VERSION ""

NS_ :

BS_:

BU_: SME EDME REME KLE GWS RDME

BO_ 3221225472 VECTOR__INDEPENDENT_SIG_MSG: 0 Vector__XXX
 SG_ FC_Contactor_Test : 0|1@0+ (1,0) [0|1] "" Vector__XXX
 SG_ Displayed_SOC : 0|8@1+ (0.5,0) [0|100] "%" Vector__XXX
 SG_ CV_Setpoint : 0|12@1+ (0.1,0) [0|409.4] "Volts" Vector__XXX
 SG_ New_Signal_79 : 16|8@1+ (1,0) [0|0] "" Vector__XXX
 SG_ Frame0_1D6 : 0|8@1+ (1,0) [0|0] "" Vector__XXX
 SG_ Frame1_1D6 : 8|8@1+ (1,0) [0|0] "" Vector__XXX
 SG_ DataHighVol : 0|8@1+ (1,0) [0|0] "" Vector__XXX
 SG_ I_Available : 24|16@1+ (0.1,0) [-500|500] "Amps" Vector__XXX
 SG_ V_Avail : 8|16@1+ (0.1,0) [0|1000] "Volts" Vector__XXX
 SG_ Thresh_V : 40|16@1+ (0.1,0) [0|600] "V" Vector__XXX
 SG_ Weld_Det_En : 0|2@1+ (1,0) [0|4] "" Vector__XXX
 SG_ internal_charger_status : 2|4@1+ (1,0) [0|16] "" Vector__XXX
 SG_ CCS_Protocol : 56|8@1+ (1,0) [0|255] "" Vector__XXX
 SG_ Iso_Status : 6|2@1+ (1,0) [0|3] "" Vector__XXX
 SG_ MinV_Avail : 0|16@1+ (0.1,0) [0|1000] "Volts" Vector__XXX
 SG_ Min_I_Avail : 16|12@1+ (0.1,0) [0|410] "A" Vector__XXX
 SG_ Energy_Transmitted : 56|8@1+ (0.25,0) [0|63] "kWh" Vector__XXX
 SG_ Power_Limit : 52|2@1+ (1,0) [0|2] "" Vector__XXX
 SG_ Battery_Compatability : 38|2@1+ (1,0) [0|4] "" Vector__XXX
 SG_ CHG_Volts : 0|16@1+ (0.1,0) [0|1] "Volts" Vector__XXX
 SG_ CHG_Amps : 16|16@1+ (0.1,0) [-500|500] "Amps" Vector__XXX
 SG_ I_Limit : 44|2@1+ (1,0) [0|1] "" Vector__XXX
 SG_ V_Limit : 46|2@1+ (1,0) [0|3] "" Vector__XXX
 SG_ Batt_Malf : 40|2@1+ (1,0) [0|3] "" Vector__XXX
 SG_ Charge_Status : 32|2@1+ (1,0) [0|3] "" Vector__XXX
 SG_ CCS_Malf : 34|2@1+ (1,0) [0|3] "" Vector__XXX
 SG_ DC_Chg_Stop : 42|2@1+ (1,0) [0|3] "" Vector__XXX
 SG_ Pilot_Current : 0|8@1+ (1,0) [0|63] "Amps" Vector__XXX
 SG_ Cable_Current : 8|8@1+ (1,0) [0|63] "Amps" Vector__XXX
 SG_ FC_Voltage : 56|8@1+ (2,0) [0|500] "Volts" Vector__XXX
 SG_ Pilot_Status : 32|3@1+ (1,0) [0|1] "" Vector__XXX
 SG_ PP_Status : 23|2@1+ (1,0) [0|1] "" Vector__XXX
 SG_ CP_Lock_Status : 26|2@1+ (1,0) [0|1] "" Vector__XXX
 SG_ CHG_Flap_Status : 24|2@1+ (1,0) [0|4] "" Vector__XXX
 SG_ Plug_Connection : 37|2@1+ (1,0) [0|4] "" Vector__XXX
 SG_ Charge_End_Sig : 20|2@1+ (1,0) [0|4] "" Vector__XXX
 SG_ HW_Charger_EN : 22|2@1+ (1,0) [0|1] "" Vector__XXX
 SG_ CCS_Plug : 35|2@1+ (1,0) [0|1] "" Vector__XXX
 SG_ Charging_Type : 48|8@1+ (1,0) [0|1] "" Vector__XXX
 SG_ DC_Chg_Volts : 39|9@1+ (2,0) [0|1000] "V" Vector__XXX
 SG_ FC_Contactor_Info : 20|4@1+ (1,0) [0|15] "" Vector__XXX
 SG_ FC_Contactor_State : 18|2@1+ (1,0) [0|3] "" Vector__XXX
 SG_ ChargeFlap_Status : 16|2@1+ (1,0) [0|4] "" Vector__XXX
 SG_ Hook_Pos : 0|2@1+ (1,0) [0|3] "" Vector__XXX
 SG_ Hook_Lock : 2|2@1+ (1,0) [0|3] "" Vector__XXX
 SG_ Chg_End : 18|2@1+ (1,0) [0|1] "" Vector__XXX
 SG_ FC_End : 16|2@1+ (1,0) [0|1] "" Vector__XXX
 SG_ Target_CHG_Ph : 20|4@1+ (1,0) [0|1] "" Vector__XXX
 SG_ Time2Go : 0|16@1+ (1,0) [0|65534] "Mins" Vector__XXX
 SG_ Target_Volts : 24|14@1+ (0.1,0) [0|1000] "V" Vector__XXX
 SG_ frame0_1d6 : 0|8@1+ (1,0) [0|0] "" Vector__XXX
 SG_ frame1_1d6 : 8|8@1+ (1,0) [0|0] "" Vector__XXX
 SG_ Frame_0_1EE : 0|8@1+ (1,0) [0|0] "" Vector__XXX
 SG_ Frame_1_1EE : 8|8@1+ (1,0) [0|0] "" Vector__XXX
 SG_ POSITION_1 : 16|16@1+ (0.005,0) [0|1] "" Vector__XXX
 SG_ lock_button : 22|2@1+ (1,0) [0|4] "" Vector__XXX
 SG_ doors : 8|8@1+ (1,0) [0|0] "" Vector__XXX
 SG_ locks : 0|8@1+ (1,0) [0|0] "" Vector__XXX
 SG_ boot : 16|6@1+ (1,0) [0|0] "" Vector__XXX
 SG_ UnusedFF : 24|40@1+ (1,0) [0|0] "" Vector__XXX
 SG_ Time_to_FC_SOC : 40|16@1+ (10,0) [0|655320] "Secs" Vector__XXX
 SG_ Time_to_SOC : 24|16@1+ (10,0) [0|655320] "Secs" Vector__XXX
 SG_ FC_SOC : 56|8@1+ (0.5,0) [0|100] "%" Vector__XXX
 SG_ CHG_I_Lim : 16|8@1+ (1,0) [0|254] "Amps" Vector__XXX
 SG_ CHG_V_Lim : 0|14@1- (0.1,0) [0|1000] "Volts" Vector__XXX
 SG_ BatteryVoltage : 16|12@1+ (1,0) [0|0] "" Vector__XXX
 SG_ Total_Battery : 40|12@1+ (0.02,0) [0|82] "kWh" Vector__XXX
 SG_ TemperatureMaxMaybe : 16|8@1+ (1,0) [0|0] "" Vector__XXX
 SG_ NewSignal_0033 : 24|4@1+ (1,0) [0|0] "" Vector__XXX
 SG_ NewSignal_0035 : 8|8@1+ (1,0) [0|0] "" Vector__XXX
 SG_ NewSignal_0039 : 8|2@1+ (1,0) [0|0] "" Vector__XXX

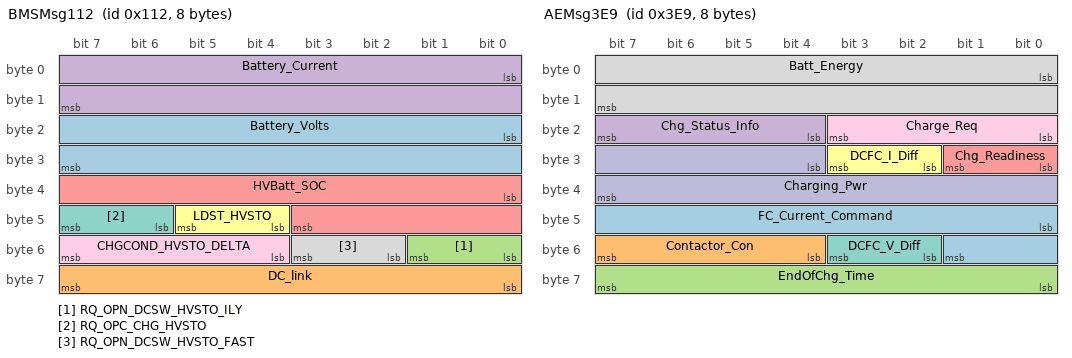
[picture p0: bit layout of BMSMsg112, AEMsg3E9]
BO_ 274 BMSMsg112: 8 SME
 SG_ Battery_Volts : 16|16@1+ (0.1,0) [0|819] "Volts" Vector__XXX
 SG_ DC_link : 56|8@1+ (4,0) [0|820] "Volts" Vector__XXX
 SG_ RQ_OPN_DCSW_HVSTO_ILY : 48|2@1+ (1,0) [0|16] "" Vector__XXX
 SG_ Battery_Current : 0|16@1+ (0.1,-819.2) [0|819.2] "Amps" Vector__XXX
 SG_ HVBatt_SOC : 32|12@1+ (0.1,0) [0|100] "%" Vector__XXX
 SG_ LDST_HVSTO : 44|2@1+ (1,0) [0|0] "" Vector__XXX
 SG_ RQ_OPC_CHG_HVSTO : 46|2@1+ (1,0) [0|0] "" Vector__XXX
 SG_ RQ_OPN_DCSW_HVSTO_FAST : 50|2@1+ (1,0) [0|3] "status" Vector__XXX
 SG_ CHGCOND_HVSTO_DELTA : 52|4@1+ (0.00834,0) [0|0.1] "%" Vector__XXX

BO_ 1001 AEMsg3E9: 8 EDME
 SG_ FC_Current_Command : 40|10@1- (1,0) [-500|500] "Amps" Vector__XXX
 SG_ Contactor_Con : 52|4@1+ (1,0) [0|16] "" Vector__XXX
 SG_ EndOfChg_Time : 56|8@1+ (1,0) [0|255] "Mins" Vector__XXX
 SG_ Chg_Status_Info : 20|4@1+ (1,0) [0|3] "" Vector__XXX
 SG_ Chg_Readiness : 24|2@1+ (1,0) [0|3] "" Vector__XXX
 SG_ DCFC_I_Diff : 26|2@1+ (1,0) [0|3] "" Vector__XXX
 SG_ DCFC_V_Diff : 50|2@1+ (1,0) [0|3] "" Vector__XXX
 SG_ Batt_Energy : 0|16@1+ (1,0) [0|65534] "Wh" Vector__XXX
 SG_ Charge_Req : 16|4@1+ (1,0) [0|16] "" Vector__XXX
 SG_ Charging_Pwr : 28|12@1+ (25,0) [0|102350] "Watts" Vector__XXX

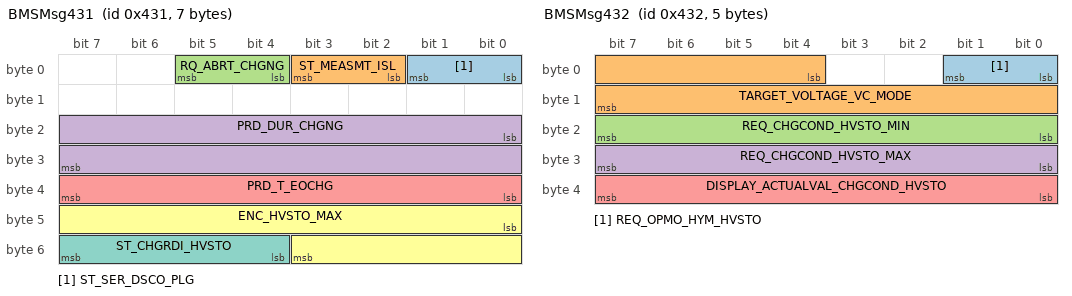
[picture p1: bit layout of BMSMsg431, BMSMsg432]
BO_ 1073 BMSMsg431: 7 SME
 SG_ ST_SER_DSCO_PLG : 0|2@1+ (1,0) [0|3] "status" Vector__XXX
 SG_ ST_MEASMT_ISL : 2|2@1+ (1,0) [0|3] "status" Vector__XXX
 SG_ RQ_ABRT_CHGNG : 4|2@1+ (1,0) [0|0] "" Vector__XXX
 SG_ PRD_DUR_CHGNG : 16|16@1+ (1,0) [0|65532] "minutes" Vector__XXX
 SG_ PRD_T_EOCHG : 32|8@1+ (1,0) [0|1270] "minutes" Vector__XXX
 SG_ ENC_HVSTO_MAX : 40|12@1+ (0.02,0) [0|81.88] "kWh" Vector__XXX
 SG_ ST_CHGRDI_HVSTO : 52|4@1+ (1,0) [0|0] "" Vector__XXX

BO_ 1074 BMSMsg432: 5 SME
 SG_ REQ_OPMO_HYM_HVSTO : 0|2@1+ (1,0) [0|3] "status" Vector__XXX
 SG_ TARGET_VOLTAGE_VC_MODE : 4|12@1+ (0.1,0) [0|409.4] "V" Vector__XXX
 SG_ REQ_CHGCOND_HVSTO_MIN : 16|8@1+ (0.5,0) [0|100] "%" Vector__XXX
 SG_ REQ_CHGCOND_HVSTO_MAX : 24|8@1+ (0.5,0) [0|100] "%" Vector__XXX
 SG_ DISPLAY_ACTUALVAL_CHGCOND_HVSTO : 32|8@1+ (0.5,0) [0|100] "%" Vector__XXX

BO_ 808 EDMEMsg328: 6 EDME
 SG_ Seconds_ctr : 0|32@1+ (1,0) [0|2704] "S" Vector__XXX
 SG_ Day_ctr : 32|16@1+ (1,0) [0|65534] "Days" Vector__XXX

BO_ 303 EDMEMsg12f: 8 EDME
 SG_ CRC_12F : 0|8@1+ (1,0) [0|255] "CRC" Vector__XXX
 SG_ ALIVE_COUNTER_KL : 8|4@1+ (1,0) [0|14] "counter" Vector__XXX
 SG_ ST_VEH_CON : 12|4@1+ (1,0) [0|15] "status" Vector__XXX
 SG_ ST_KL : 16|4@1+ (1,0) [0|15] "status" Vector__XXX
 SG_ ST_KL_DIV : 20|4@1+ (1,0) [0|15] "status" Vector__XXX
 SG_ ST_KL_30B : 24|4@1+ (1,0) [0|15] "status" Vector__XXX
 SG_ ST_KL_15N : 28|4@1+ (1,0) [0|15] "status" Vector__XXX
 SG_ ST_KL_KEY_VLD : 32|4@1+ (1,0) [0|15] "status" Vector__XXX
 SG_ ST_PLK : 36|2@1+ (1,0) [0|3] "status" Vector__XXX
 SG_ CON_CLT_SW : 38|2@1+ (1,0) [0|3] "" Vector__XXX
 SG_ CTR_ENG_STOP : 40|2@1+ (1,0) [0|3] "counter" Vector__XXX
 SG_ ST_STCD_PENG : 42|2@1+ (1,0) [0|3] "status" Vector__XXX
 SG_ ST_OP_MSA : 44|2@1+ (1,0) [0|3] "status" Vector__XXX
 SG_ ST_SSP : 46|2@1+ (1,0) [0|3] "status" Vector__XXX
 SG_ RWDT_BLS : 48|4@1+ (1,0) [0|15] "" Vector__XXX
 SG_ ST_KL_50_MSA : 52|2@1+ (1,0) [0|3] "status" Vector__XXX
 SG_ RQ_DRVG_RDI : 54|2@1+ (1,0) [0|3] "" Vector__XXX
 SG_ ST_KL_DBG : 56|8@1+ (1,0) [0|255] "status" Vector__XXX

BO_ 1000 AEMsg3e8: 2 EDME
 SG_ RQ_MIL_DIAG_OBD_ENGMG_EL : 0|2@1+ (1,0) [0|4] "" Vector__XXX
 SG_ RQ_RST_OBD_DIAG : 2|2@1+ (1,0) [0|0] "" Vector__XXX

BO_ 816 OdometerMsg330: 8 EDME
 SG_ Odometer : 0|24@1+ (1,0) [0|16777200] "km" Vector__XXX

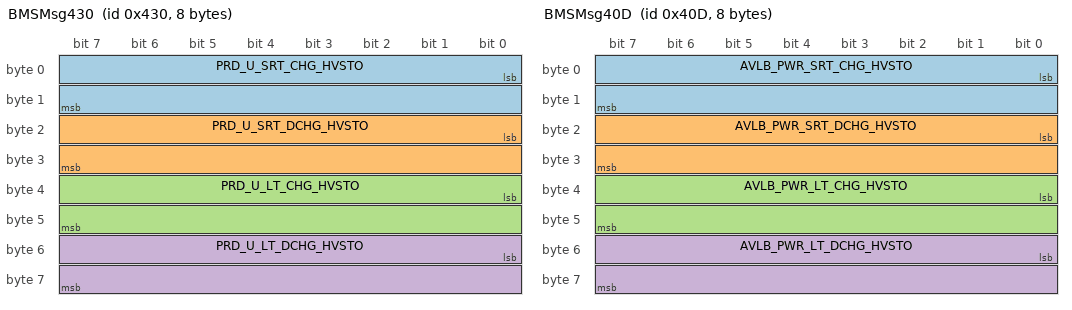
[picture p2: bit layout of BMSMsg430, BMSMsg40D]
BO_ 1072 BMSMsg430: 8 SME
 SG_ PRD_U_SRT_CHG_HVSTO : 0|16@1+ (1,0.1) [0|819] "V" Vector__XXX
 SG_ PRD_U_SRT_DCHG_HVSTO : 16|16@1+ (1,0.1) [0|819] "V" Vector__XXX
 SG_ PRD_U_LT_CHG_HVSTO : 32|16@1+ (1,0.1) [0|819] "V" Vector__XXX
 SG_ PRD_U_LT_DCHG_HVSTO : 48|16@1+ (1,0.1) [0|819] "V" Vector__XXX

BO_ 506 BMSMsg1FA: 8 SME
 SG_ ST_ERR_ISL_EXTN_BN_HV : 0|2@1+ (1,0) [0|3] "status" Vector__XXX
 SG_ ST_ERR_ISL_INTL_BN_HV : 2|2@1+ (1,0) [0|3] "status" Vector__XXX
 SG_ RQ_COOL_HVSTO : 4|2@1+ (1,0) [0|3] "status" Vector__XXX
 SG_ ST_VA_COOL_HVSTO : 6|2@1+ (1,0) [0|3] "status" Vector__XXX
 SG_ ST_ERR_LOKG_HVSTO : 8|2@1+ (1,0) [0|3] "status" Vector__XXX
 SG_ ST_PRCHRG_LOKD_HVSTO : 10|2@1+ (1,0) [0|3] "status" Vector__XXX
 SG_ ST_DCSW_HVSTO : 12|2@1+ (1,0) [0|3] "status" Vector__XXX
 SG_ ST_EMMOD_HVSTO : 14|2@1+ (1,0) [0|3] "status" Vector__XXX
 SG_ RQ_SER_HVSTO : 16|2@1+ (1,0) [0|3] "status" Vector__XXX
 SG_ ERR_EMMOD_HVSTO : 18|2@1+ (1,0) [0|3] "status" Vector__XXX
 SG_ ST_ERR_DCSW_HVSTO : 20|2@1+ (1,0) [0|3] "status" Vector__XXX
 SG_ ST_WARN_ISL_BN_HV : 22|2@1+ (1,0) [0|3] "status" Vector__XXX
 SG_ ST_CSOV_HVSTO : 24|4@1+ (1,0) [0|15] "status" Vector__XXX
 SG_ AVL_TEMP_HVSTO : 32|8@1+ (1,-50) [-50|204] "C" Vector__XXX
 SG_ AVL_TEMP_HTEX_HVSTO : 40|8@1+ (1,-50) [-50|204] "C" Vector__XXX
 SG_ AVL_TEMP_HVSTO_MIN : 48|8@1+ (1,-50) [-50|202] "C" Vector__XXX
 SG_ AVL_TEMP_HVSTO_MAX : 56|8@1+ (1,-50) [-50|202] "C" Vector__XXX

BO_ 1037 BMSMsg40D: 8 SME
 SG_ AVLB_PWR_SRT_CHG_HVSTO : 0|16@1+ (3,0) [0|196596] "W" Vector__XXX
 SG_ AVLB_PWR_SRT_DCHG_HVSTO : 16|16@1+ (3,0) [0|196596] "W" Vector__XXX
 SG_ AVLB_PWR_LT_CHG_HVSTO : 32|16@1+ (3,0) [0|196596] "W" Vector__XXX
 SG_ AVLB_PWR_LT_DCHG_HVSTO : 48|16@1+ (3,0) [0|196596] "W" Vector__XXX

BO_ 767 BMSMsg2FF: 6 SME
 SG_ AVL_PWR_HT_HVSTO : 4|12@1+ (1,0) [0|4094] "W" Vector__XXX

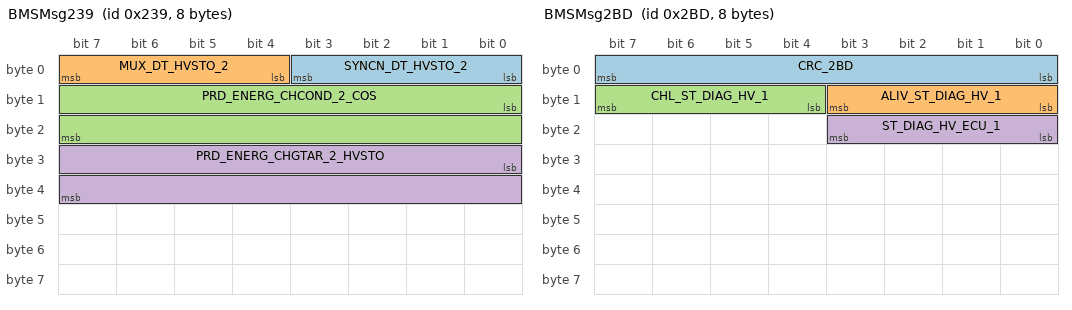
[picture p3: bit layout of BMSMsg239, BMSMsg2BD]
BO_ 569 BMSMsg239: 8 SME
 SG_ SYNCN_DT_HVSTO_2 : 0|4@1+ (1,0) [0|14] "" Vector__XXX
 SG_ MUX_DT_HVSTO_2 : 4|4@1+ (1,0) [0|0] "" Vector__XXX
 SG_ PRD_ENERG_CHCOND_2_COS : 8|16@1+ (1,0) [0|65534] "Wh" Vector__XXX
 SG_ PRD_ENERG_CHGTAR_2_HVSTO : 24|16@1+ (0.02,0) [0|1310.64] "kWh" Vector__XXX

BO_ 701 BMSMsg2BD: 8 SME
 SG_ CRC_2BD : 0|8@1+ (1,0) [0|0] "" Vector__XXX
 SG_ ALIV_ST_DIAG_HV_1 : 8|4@1+ (1,0) [0|15] "counter" Vector__XXX
 SG_ CHL_ST_DIAG_HV_1 : 12|4@1+ (1,0) [0|15] "counter" Vector__XXX
 SG_ ST_DIAG_HV_ECU_1 : 16|4@1+ (1,0) [0|15] "status" Vector__XXX

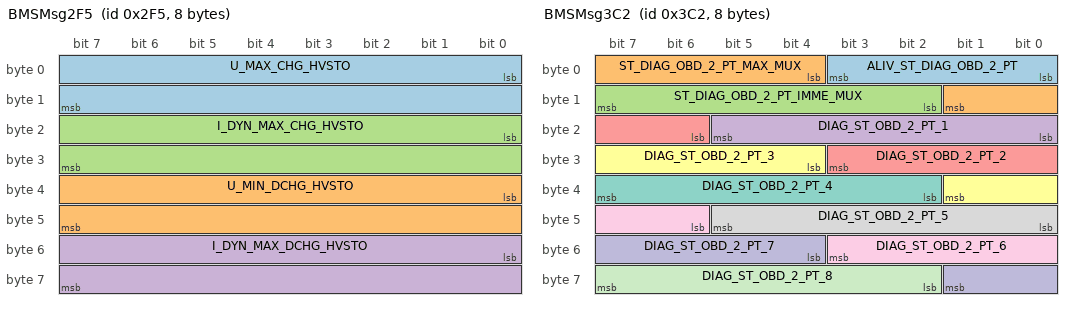
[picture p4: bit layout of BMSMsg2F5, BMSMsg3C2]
BO_ 757 BMSMsg2F5: 8 SME
 SG_ U_MAX_CHG_HVSTO : 0|16@1+ (0.1,0) [0|819] "V" Vector__XXX
 SG_ U_MIN_DCHG_HVSTO : 32|16@1+ (0.1,0) [0|819] "V" Vector__XXX
 SG_ I_DYN_MAX_CHG_HVSTO : 16|16@1+ (0.1,-819.2) [-819.2|819] "A" Vector__XXX
 SG_ I_DYN_MAX_DCHG_HVSTO : 48|16@1+ (0.1,-819.2) [-819.2|819] "A" Vector__XXX

BO_ 962 BMSMsg3C2: 8 SME
 SG_ ALIV_ST_DIAG_OBD_2_PT : 0|4@1+ (1,0) [0|15] "counter" Vector__XXX
 SG_ ST_DIAG_OBD_2_PT_MAX_MUX : 4|6@1+ (1,0) [4|60] "mux" Vector__XXX
 SG_ ST_DIAG_OBD_2_PT_IMME_MUX : 10|6@1+ (1,0) [4|60] "mux" Vector__XXX
 SG_ DIAG_ST_OBD_2_PT_1 : 16|6@1+ (1,0) [0|0] "" Vector__XXX
 SG_ DIAG_ST_OBD_2_PT_2 : 22|6@1+ (1,0) [0|0] "" Vector__XXX
 SG_ DIAG_ST_OBD_2_PT_3 : 28|6@1+ (1,0) [0|0] "" Vector__XXX
 SG_ DIAG_ST_OBD_2_PT_4 : 34|6@1+ (1,0) [0|0] "" Vector__XXX
 SG_ DIAG_ST_OBD_2_PT_5 : 40|6@1+ (1,0) [0|0] "" Vector__XXX
 SG_ DIAG_ST_OBD_2_PT_6 : 46|6@1+ (1,0) [0|0] "" Vector__XXX
 SG_ DIAG_ST_OBD_2_PT_7 : 52|6@1+ (1,0) [0|0] "" Vector__XXX
 SG_ DIAG_ST_OBD_2_PT_8 : 58|6@1+ (1,0) [0|0] "" Vector__XXX

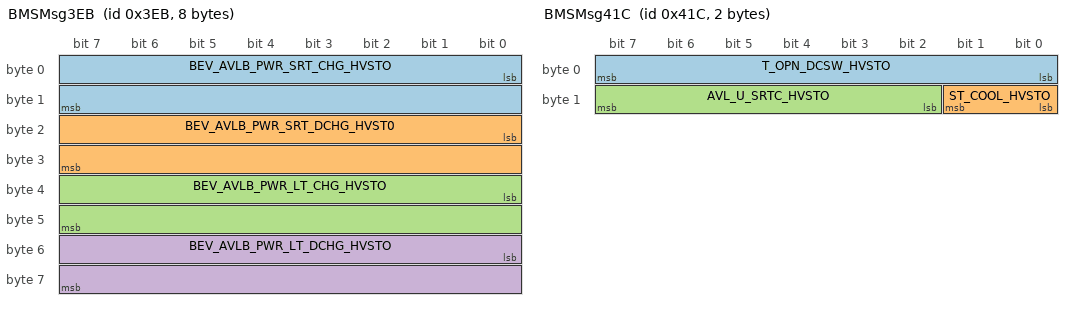
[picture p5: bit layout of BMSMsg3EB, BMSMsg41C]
BO_ 1003 BMSMsg3EB: 8 SME
 SG_ BEV_AVLB_PWR_SRT_CHG_HVSTO : 0|16@1+ (3,0) [0|196602] "W" Vector__XXX
 SG_ BEV_AVLB_PWR_SRT_DCHG_HVST0 : 16|16@1+ (3,0) [0|196602] "W" Vector__XXX
 SG_ BEV_AVLB_PWR_LT_CHG_HVSTO : 32|16@1+ (3,0) [0|196602] "W" Vector__XXX
 SG_ BEV_AVLB_PWR_LT_DCHG_HVSTO : 48|16@1+ (3,0) [0|196602] "W" Vector__XXX

BO_ 867 BMSMsg363: 8 SME
 SG_ IDENT_HVSTO : 0|32@1+ (1,0) [0|4294967295] "serial" Vector__XXX

BO_ 1287 BMSMsg507: 8 SME
 SG_ NM2_AUTOSAR_RES_ACAN : 0|32@1+ (1,0) [0|0] "" Vector__XXX
 SG_ NM2_USR_DT_ACAN : 32|32@1+ (1,0) [0|0] "" Vector__XXX

BO_ 1415 BMSMsg587: 8 SME
 SG_ ID2 : 0|8@1+ (1,0) [0|0] "" Vector__XXX
 SG_ DT_Dynamic : 8|56@1+ (1,0) [0|0] "" Vector__XXX

BO_ 1052 BMSMsg41C: 2 SME
 SG_ T_OPN_DCSW_HVSTO : 0|8@1+ (1,0) [0|0] "" Vector__XXX
 SG_ ST_COOL_HVSTO : 8|2@1+ (1,0) [0|3] "status" Vector__XXX
 SG_ AVL_U_SRTC_HVSTO : 10|6@1+ (1,0) [0|0] "" Vector__XXX

BO_ 1543 BMSMsg607: 8 SME

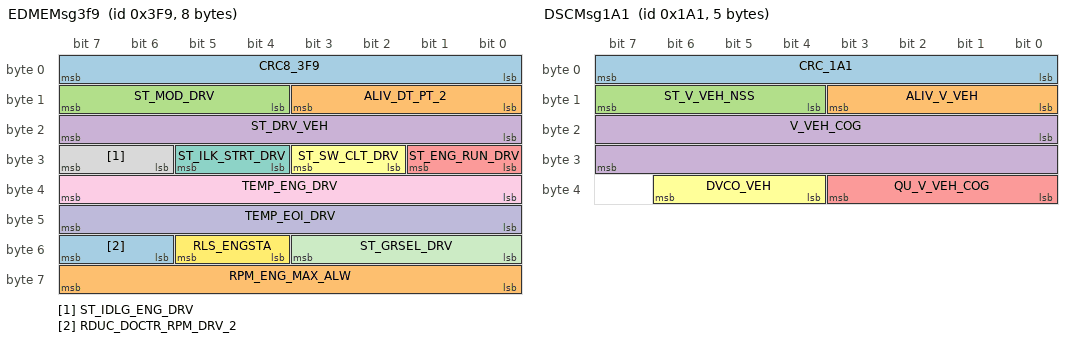
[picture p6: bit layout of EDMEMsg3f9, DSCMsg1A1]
BO_ 1017 EDMEMsg3f9: 8 EDME
 SG_ CRC8_3F9 : 0|8@1+ (1,0) [0|255] "CRC" Vector__XXX
 SG_ ALIV_DT_PT_2 : 8|4@1+ (1,0) [0|16] "counter" Vector__XXX
 SG_ ST_MOD_DRV : 12|4@1+ (1,0) [0|16] "status" Vector__XXX
 SG_ ST_DRV_VEH : 16|8@1+ (1,0) [0|0] "status" Vector__XXX
 SG_ ST_ENG_RUN_DRV : 24|2@1+ (1,0) [0|0] "status" Vector__XXX
 SG_ ST_SW_CLT_DRV : 26|2@1+ (1,0) [0|0] "status" Vector__XXX
 SG_ ST_ILK_STRT_DRV : 28|2@1+ (1,0) [0|0] "status" Vector__XXX
 SG_ ST_IDLG_ENG_DRV : 30|2@1+ (1,0) [0|0] "" Vector__XXX
 SG_ TEMP_ENG_DRV : 32|8@1+ (1,-48) [-48|144] "" Vector__XXX
 SG_ TEMP_EOI_DRV : 40|8@1+ (1,-48) [-48|170] "" Vector__XXX
 SG_ ST_GRSEL_DRV : 48|4@1+ (1,0) [0|0] "" Vector__XXX
 SG_ RLS_ENGSTA : 52|2@1+ (1,0) [0|0] "" Vector__XXX
 SG_ RDUC_DOCTR_RPM_DRV_2 : 54|2@1+ (1,0) [0|0] "" Vector__XXX
 SG_ RPM_ENG_MAX_ALW : 56|8@1+ (1,0) [0|0] "" Vector__XXX

BO_ 417 DSCMsg1A1: 5 Vector__XXX
 SG_ CRC_1A1 : 0|8@1+ (1,0) [0|255] "CRCV" Vector__XXX
 SG_ ALIV_V_VEH : 8|4@1+ (1,0) [0|15] "counter" Vector__XXX
 SG_ ST_V_VEH_NSS : 12|4@1+ (1,0) [0|0] "" Vector__XXX
 SG_ V_VEH_COG : 16|16@1+ (0.015625,0) [0|350] "km/h" Vector__XXX
 SG_ QU_V_VEH_COG : 32|4@1+ (1,0) [0|0] "status" Vector__XXX
 SG_ DVCO_VEH : 36|3@1+ (1,0) [0|0] "" Vector__XXX

BO_ 896 VINMsg380: 7 EDME
 SG_ VIN : 0|56@1+ (1,0) [0|0] "" Vector__XXX

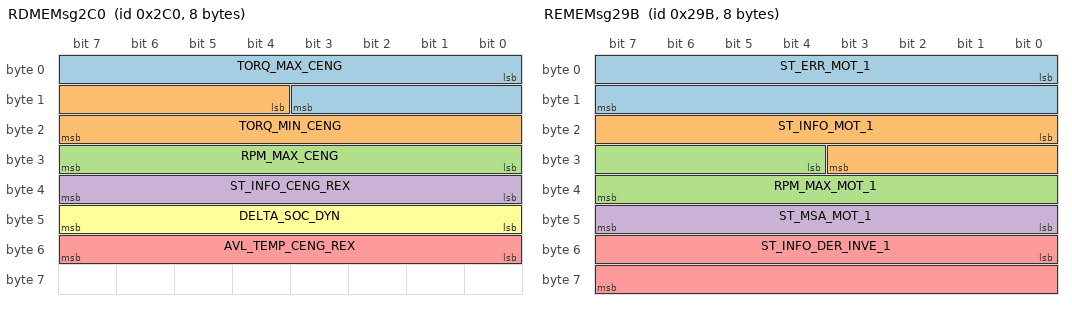
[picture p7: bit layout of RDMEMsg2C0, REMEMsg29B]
BO_ 704 RDMEMsg2C0: 8 REME
 SG_ TORQ_MAX_CENG : 0|12@1+ (0.5,-1023.5) [-1023.5|1022.5] "Nm" Vector__XXX
 SG_ TORQ_MIN_CENG : 12|12@1+ (0.5,-1023.5) [-1023.5|1022.5] "Nm" Vector__XXX
 SG_ RPM_MAX_CENG : 24|8@1+ (40,0) [0|10000] "rpm" Vector__XXX
 SG_ ST_INFO_CENG_REX : 32|8@1+ (1,0) [0|255] "status" Vector__XXX
 SG_ AVL_TEMP_CENG_REX : 48|8@1+ (1,-48) [-48|204] "C" Vector__XXX
 SG_ DELTA_SOC_DYN : 40|8@1+ (1,0) [0|0] "" Vector__XXX

BO_ 165 UnknownMsg0A5: 8 Vector__XXX

BO_ 168 UnknownMsg0A8: 8 Vector__XXX

BO_ 205 UnknownMsg0CD: 8 Vector__XXX

BO_ 667 REMEMsg29B: 8 REME
 SG_ ST_ERR_MOT_1 : 0|16@1+ (1,0) [0|65535] "status" Vector__XXX
 SG_ ST_INFO_MOT_1 : 16|12@1+ (1,0) [0|4095] "status" Vector__XXX
 SG_ RPM_MAX_MOT_1 : 28|12@1+ (5,0) [0|20460] "rpm" Vector__XXX
 SG_ ST_MSA_MOT_1 : 40|8@1+ (1,0) [0|255] "status" Vector__XXX
 SG_ ST_INFO_DER_INVE_1 : 48|16@1+ (1,0) [0|65535] "status" Vector__XXX

BO_ 668 UnknownMsg29C: 8 Vector__XXX

BO_ 669 UnknownMsg29D: 8 Vector__XXX

BO_ 407 UnknownMsg197: 4 EDME
 SG_ counter_197 : 8|4@1+ (1,0) [0|14] "" Vector__XXX

BO_ 1290 UnknownMsg50A: 8 Vector__XXX
 SG_ NM2_AUTOSAR_RES_ACAN_50A : 0|32@1+ (1,0) [0|0] "" Vector__XXX
 SG_ NM2_USR_DT_ACAN_50A : 32|32@1+ (1,0) [0|0] "" Vector__XXX

BO_ 748 UnknownMsg2EC: 2 Vector__XXX

BO_ 1289 UnknownMsg509: 8 Vector__XXX

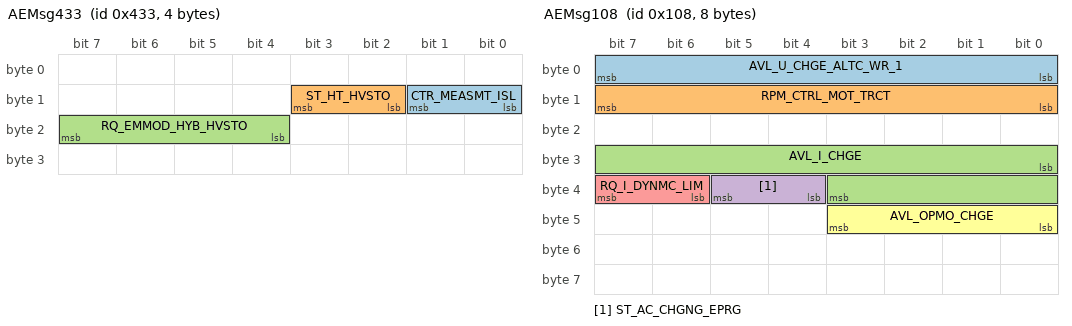
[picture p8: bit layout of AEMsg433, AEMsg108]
BO_ 1075 AEMsg433: 4 EDME
 SG_ CTR_MEASMT_ISL : 8|2@1+ (1,0) [0|0] "" Vector__XXX
 SG_ ST_HT_HVSTO : 10|2@1+ (1,0) [0|3] "status" Vector__XXX
 SG_ RQ_EMMOD_HYB_HVSTO : 20|4@1+ (1,0) [0|15] "status" Vector__XXX

BO_ 339 UnknownMsg153: 8 Vector__XXX

BO_ 173 UnknownMsg0AD: 8 Vector__XXX

BO_ 187 UnknownMsg0BB: 3 Vector__XXX

BO_ 256 UnknownMsg100: 8 Vector__XXX

BO_ 264 AEMsg108: 8 EDME
 SG_ AVL_U_CHGE_ALTC_WR_1 : 0|8@1+ (1,0) [0|254] "V" Vector__XXX
 SG_ RPM_CTRL_MOT_TRCT : 8|8@1+ (2.025,-255) [-255|255] "Nm" Vector__XXX
 SG_ AVL_I_CHGE : 24|12@1+ (0.1,-204.7) [-204.7|204.7] "A" Vector__XXX
 SG_ ST_AC_CHGNG_EPRG : 36|2@1+ (1,0) [0|3] "status" Vector__XXX
 SG_ RQ_I_DYNMC_LIM : 38|2@1+ (1,0) [0|3] "status" Vector__XXX
 SG_ AVL_OPMO_CHGE : 40|4@1+ (1,0) [0|15] "status" Vector__XXX

BO_ 317 UnknownMsg13D: 8 Vector__XXX

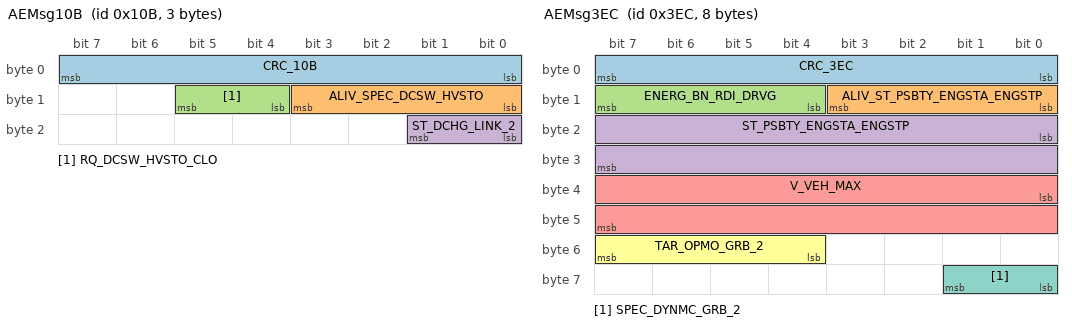
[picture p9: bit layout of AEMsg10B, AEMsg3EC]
BO_ 267 AEMsg10B: 3 Vector__XXX
 SG_ CRC_10B : 0|8@1+ (1,0) [0|0] "255" Vector__XXX
 SG_ ALIV_SPEC_DCSW_HVSTO : 8|4@1+ (1,0) [0|14] "counter" Vector__XXX
 SG_ RQ_DCSW_HVSTO_CLO : 12|2@1+ (1,0) [0|3] "status" Vector__XXX
 SG_ ST_DCHG_LINK_2 : 16|2@1+ (1,0) [0|3] "status" Vector__XXX

BO_ 318 UnknownMsg13E: 8 Vector__XXX

BO_ 402 UnknownMsg192: 8 Vector__XXX

BO_ 695 UnknownMsg2B7: 8 Vector__XXX

BO_ 738 UnknownMsg2E2: 8 Vector__XXX

BO_ 744 UnknownMsg2E8: 8 Vector__XXX

BO_ 815 UnknownMsg32F: 8 Vector__XXX

BO_ 932 UnknownMsg3A4: 8 Vector__XXX

BO_ 997 AEMsg3E5: 3 Vector__XXX
 SG_ ST_HV_RDI : 0|2@1+ (1,0) [0|0] "" Vector__XXX

BO_ 1004 AEMsg3EC: 8 Vector__XXX
 SG_ CRC_3EC : 0|8@1+ (1,0) [0|255] "CRC" Vector__XXX
 SG_ ALIV_ST_PSBTY_ENGSTA_ENGSTP : 8|4@1+ (1,0) [0|15] "counter" Vector__XXX
 SG_ ENERG_BN_RDI_DRVG : 12|4@1+ (1,0) [0|15] "status" Vector__XXX
 SG_ ST_PSBTY_ENGSTA_ENGSTP : 16|16@1+ (1,0) [0|0] "status" Vector__XXX
 SG_ V_VEH_MAX : 32|16@1+ (0.015625,0) [0|350] "km/h" Vector__XXX
 SG_ TAR_OPMO_GRB_2 : 52|4@1+ (1,0) [0|15] "status" Vector__XXX
 SG_ SPEC_DYNMC_GRB_2 : 56|2@1+ (1,0) [0|3] "status" Vector__XXX

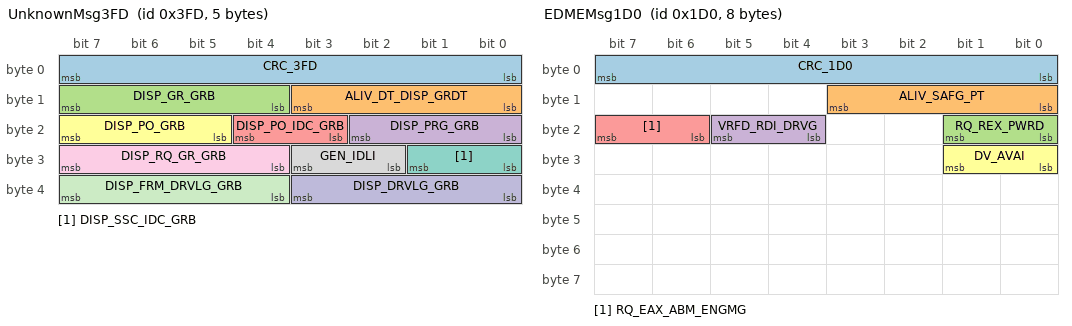
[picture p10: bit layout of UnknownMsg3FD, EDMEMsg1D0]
BO_ 1021 UnknownMsg3FD: 5 Vector__XXX
 SG_ CRC_3FD : 0|8@1+ (1,0) [0|0] "" Vector__XXX
 SG_ ALIV_DT_DISP_GRDT : 8|4@1+ (1,0) [0|0] "" Vector__XXX
 SG_ DISP_GR_GRB : 12|4@1+ (1,0) [0|15] "status" Vector__XXX
 SG_ DISP_PRG_GRB : 16|3@1+ (1,0) [0|7] "status" Vector__XXX
 SG_ DISP_PO_IDC_GRB : 19|2@1+ (1,0) [0|3] "status" Vector__XXX
 SG_ DISP_PO_GRB : 21|3@1+ (1,0) [0|7] "status" Vector__XXX
 SG_ DISP_SSC_IDC_GRB : 24|2@1+ (1,0) [0|3] "status" Vector__XXX
 SG_ GEN_IDLI : 26|2@1+ (1,0) [0|3] "status" Vector__XXX
 SG_ DISP_RQ_GR_GRB : 28|4@1+ (1,0) [0|15] "status" Vector__XXX
 SG_ DISP_DRVLG_GRB : 32|4@1+ (1,0) [0|0] "" Vector__XXX
 SG_ DISP_FRM_DRVLG_GRB : 36|4@1+ (1,0) [0|0] "" Vector__XXX

BO_ 1065 AEMsg429: 3 Vector__XXX
 SG_ AVL_I_HV_DCDC : 0|12@1+ (0.05,-102.4) [-102.4|102.3] "A" Vector__XXX
 SG_ ST_CHGNG_HV_PWMG : 16|8@1+ (1,0) [0|255] "status" Vector__XXX

BO_ 1298 UnknownMsg512: 8 Vector__XXX

BO_ 261 UnknownMsg105: 8 Vector__XXX
 SG_ CRC8_105 : 0|8@1+ (1,0) [0|255] "CRC" Vector__XXX

BO_ 464 EDMEMsg1D0: 8 EDME
 SG_ CRC_1D0 : 0|8@1+ (1,0) [0|255] "CRC" Vector__XXX
 SG_ ALIV_SAFG_PT : 8|4@1+ (1,0) [0|14] "counter" Vector__XXX
 SG_ RQ_REX_PWRD : 16|2@1+ (1,0) [0|0] "" Vector__XXX
 SG_ VRFD_RDI_DRVG : 20|2@1+ (1,0) [0|0] "" Vector__XXX
 SG_ RQ_EAX_ABM_ENGMG : 22|2@1+ (1,0) [0|0] "" Vector__XXX
 SG_ DV_AVAI : 24|2@1+ (1,0) [0|0] "" Vector__XXX

BO_ 414 UnknownMsg19E: 8 EDME

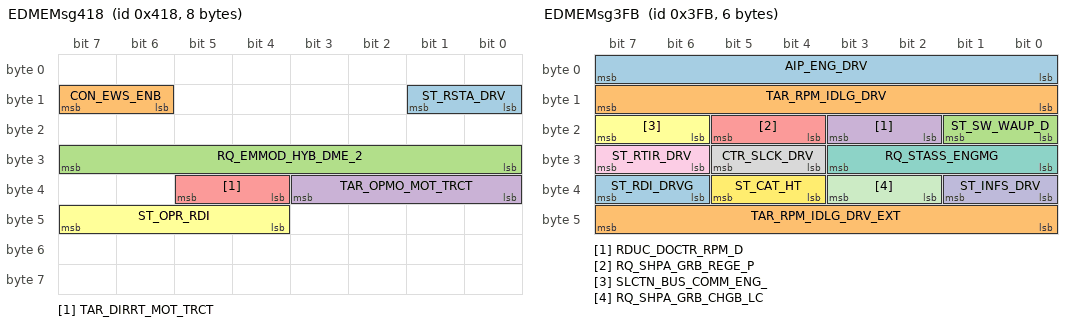
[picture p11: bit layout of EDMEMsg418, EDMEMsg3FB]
BO_ 1048 EDMEMsg418: 8 EDME
 SG_ ST_RSTA_DRV : 8|2@1+ (1,0) [0|0] "status" Vector__XXX
 SG_ CON_EWS_ENB : 14|2@1+ (1,0) [0|0] "condition" Vector__XXX
 SG_ RQ_EMMOD_HYB_DME_2 : 24|8@1+ (1,0) [0|0] "request" Vector__XXX
 SG_ TAR_OPMO_MOT_TRCT : 32|4@1+ (1,0) [0|0] "target" Vector__XXX
 SG_ TAR_DIRRT_MOT_TRCT : 36|2@1+ (1,0) [0|0] "target" Vector__XXX
 SG_ ST_OPR_RDI : 44|4@1+ (1,0) [0|0] "status" Vector__XXX

BO_ 691 UnknownMsg2B3: 8 Vector__XXX

BO_ 969 UnknownMsg3C9: 8 Vector__XXX

BO_ 1019 EDMEMsg3FB: 6 EDME
 SG_ AIP_ENG_DRV : 0|8@1+ (1,0) [0|0] "" Vector__XXX
 SG_ TAR_RPM_IDLG_DRV : 8|8@1+ (1,0) [0|0] "" Vector__XXX
 SG_ ST_SW_WAUP_D : 16|2@1+ (1,0) [0|0] "" Vector__XXX
 SG_ RDUC_DOCTR_RPM_D : 18|2@1+ (1,0) [0|0] "" Vector__XXX
 SG_ RQ_SHPA_GRB_REGE_P : 20|2@1+ (1,0) [0|0] "" Vector__XXX
 SG_ SLCTN_BUS_COMM_ENG_ : 22|2@1+ (1,0) [0|0] "" Vector__XXX
 SG_ RQ_STASS_ENGMG : 24|4@1+ (1,0) [0|0] "" Vector__XXX
 SG_ CTR_SLCK_DRV : 28|2@1+ (1,0) [0|0] "" Vector__XXX
 SG_ ST_RTIR_DRV : 30|2@1+ (1,0) [0|0] "" Vector__XXX
 SG_ ST_INFS_DRV : 32|2@1+ (1,0) [0|0] "" Vector__XXX
 SG_ RQ_SHPA_GRB_CHGB_LC : 34|2@1+ (1,0) [0|0] "" Vector__XXX
 SG_ ST_CAT_HT : 36|2@1+ (1,0) [0|0] "status" Vector__XXX
 SG_ ST_RDI_DRVG : 38|2@1+ (1,0) [0|0] "status" Vector__XXX
 SG_ TAR_RPM_IDLG_DRV_EXT : 40|8@1+ (10,0) [0|0] "l/min" Vector__XXX

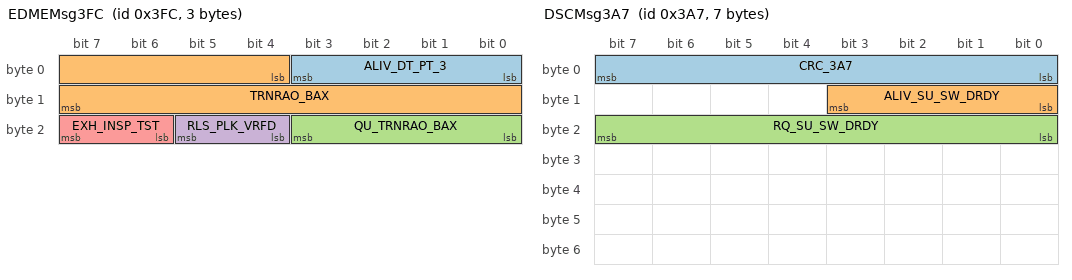
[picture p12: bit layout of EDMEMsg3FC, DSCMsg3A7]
BO_ 1020 EDMEMsg3FC: 3 EDME
 SG_ ALIV_DT_PT_3 : 0|4@1+ (1,0) [0|15] "counter" Vector__XXX
 SG_ TRNRAO_BAX : 4|12@1+ (0.002,0) [0|8.188] "ratio" Vector__XXX
 SG_ QU_TRNRAO_BAX : 16|4@1+ (1,0) [0|0] "" Vector__XXX
 SG_ RLS_PLK_VRFD : 20|2@1+ (1,0) [0|3] "status" Vector__XXX
 SG_ EXH_INSP_TST : 22|2@1+ (1,0) [0|3] "status" Vector__XXX

BO_ 170 UnknownMsg0AA: 8 Vector__XXX

BO_ 270 UnknownMsg10E: 8 Vector__XXX

BO_ 336 UnknownMsg150: 8 Vector__XXX

BO_ 426 UnknownMsg1AA: 8 Vector__XXX

BO_ 529 UnknownMsg211: 7 Vector__XXX

BO_ 702 UnknownMsg2BE: 8 Vector__XXX

BO_ 714 UnknownMsg2CA: 2 Vector__XXX

BO_ 739 UnknownMsg2E3: 8 Vector__XXX

BO_ 806 UnknownMsg326: 8 Vector__XXX

BO_ 935 DSCMsg3A7: 7 Vector__XXX
 SG_ CRC_3A7 : 0|8@1+ (1,0) [0|0] "" Vector__XXX
 SG_ ALIV_SU_SW_DRDY : 8|4@1+ (1,0) [0|0] "" Vector__XXX
 SG_ RQ_SU_SW_DRDY : 16|8@1+ (1,0) [0|0] "" Vector__XXX

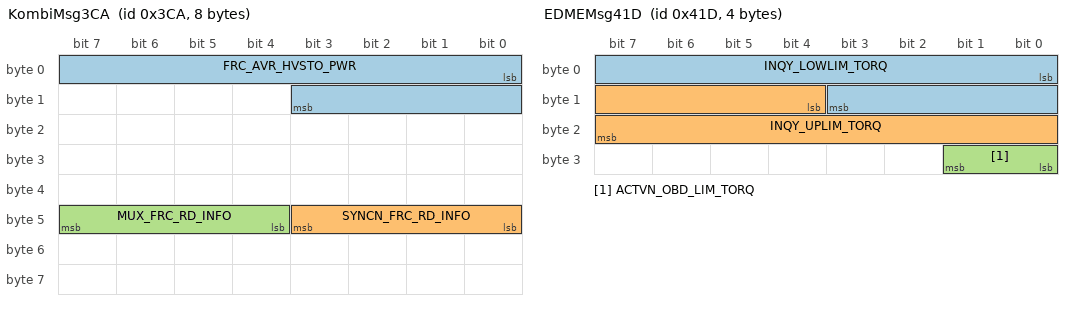
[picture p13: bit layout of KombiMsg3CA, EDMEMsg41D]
BO_ 970 KombiMsg3CA: 8 Vector__XXX
 SG_ FRC_AVR_HVSTO_PWR : 0|12@1+ (0.05,0) [0|204.7] "kW" Vector__XXX
 SG_ SYNCN_FRC_RD_INFO : 40|4@1+ (1,0) [0|0] "" Vector__XXX
 SG_ MUX_FRC_RD_INFO : 44|4@1+ (1,0) [0|0] "" Vector__XXX

BO_ 976 UnknownMsg3D0: 2 Vector__XXX

BO_ 1053 EDMEMsg41D: 4 EDME
 SG_ INQY_LOWLIM_TORQ : 0|12@1+ (0.5,-1023.5) [-1023.5|1023.5] "Nm" Vector__XXX
 SG_ INQY_UPLIM_TORQ : 12|12@1+ (0.5,-1023.5) [-1023.5|1023.5] "Nm" Vector__XXX
 SG_ ACTVN_OBD_LIM_TORQ : 24|2@1+ (1,0) [0|0] "" Vector__XXX

BO_ 1301 UnknownMsg515: 8 Vector__XXX

BO_ 1306 UnknownMsg51A: 8 Vector__XXX

BO_ 1374 UnknownMsg55E: 8 Vector__XXX

BO_ 1434 AEMsg59A: 8 Vector__XXX

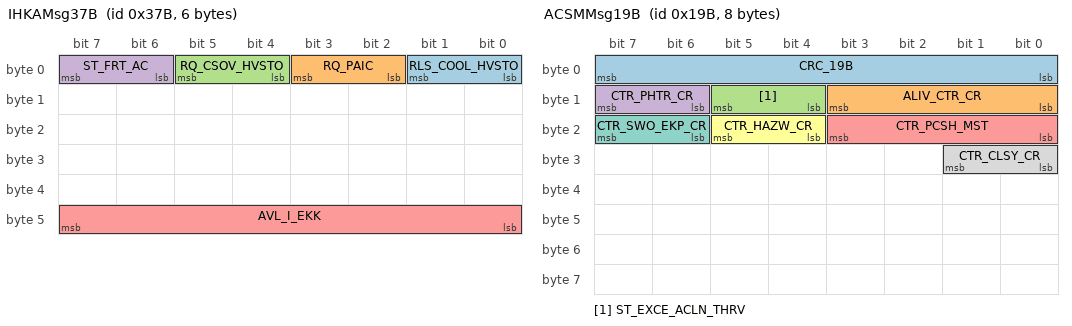
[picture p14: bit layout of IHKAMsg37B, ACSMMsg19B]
BO_ 891 IHKAMsg37B: 6 Vector__XXX
 SG_ RLS_COOL_HVSTO : 0|2@1+ (1,0) [0|3] "" Vector__XXX
 SG_ RQ_PAIC : 2|2@1+ (1,0) [0|3] "" Vector__XXX
 SG_ RQ_CSOV_HVSTO : 4|2@1+ (1,0) [0|3] "" Vector__XXX
 SG_ ST_FRT_AC : 6|2@1+ (1,0) [0|3] "status" Vector__XXX
 SG_ AVL_I_EKK : 40|8@1+ (0.2,0) [0|50.8] "A" Vector__XXX

BO_ 996 IHKAMsg3E4: 8 Vector__XXX
 SG_ AVL_I_EL_GEY : 8|8@1+ (0.2,0) [0|0] "50.8" Vector__XXX

BO_ 1528 IHKAMsg5F8: 8 Vector__XXX

BO_ 411 ACSMMsg19B: 8 Vector__XXX
 SG_ CRC_19B : 0|8@1+ (1,0) [0|255] "CRC" Vector__XXX
 SG_ ALIV_CTR_CR : 8|4@1+ (1,0) [0|14] "counter" Vector__XXX
 SG_ ST_EXCE_ACLN_THRV : 12|2@1+ (1,0) [0|0] "" Vector__XXX
 SG_ CTR_PHTR_CR : 14|2@1+ (1,0) [0|0] "" Vector__XXX
 SG_ CTR_PCSH_MST : 16|4@1+ (1,0) [0|0] "" Vector__XXX
 SG_ CTR_HAZW_CR : 20|2@1+ (1,0) [0|0] "" Vector__XXX
 SG_ CTR_SWO_EKP_CR : 22|2@1+ (1,0) [0|0] "" Vector__XXX
 SG_ CTR_CLSY_CR : 24|2@1+ (1,0) [0|0] "" Vector__XXX

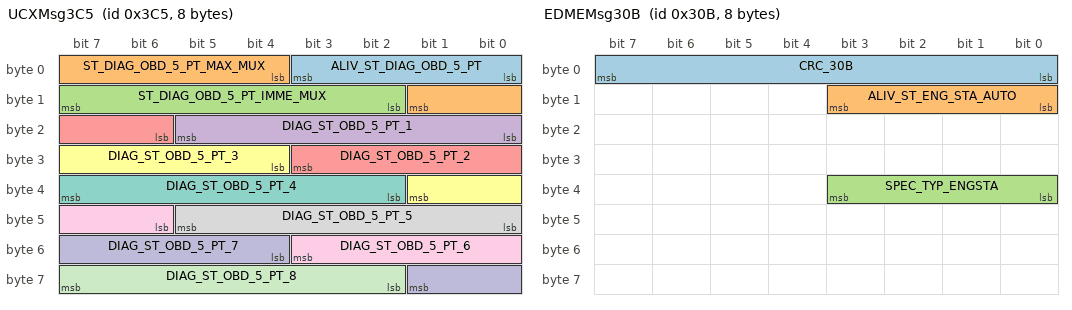
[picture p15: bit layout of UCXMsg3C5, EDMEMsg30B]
BO_ 965 UCXMsg3C5: 8 Vector__XXX
 SG_ ALIV_ST_DIAG_OBD_5_PT : 0|4@1+ (1,0) [0|0] "" Vector__XXX
 SG_ ST_DIAG_OBD_5_PT_MAX_MUX : 4|6@1+ (1,0) [0|0] "" Vector__XXX
 SG_ ST_DIAG_OBD_5_PT_IMME_MUX : 10|6@1+ (1,0) [0|0] "" Vector__XXX
 SG_ DIAG_ST_OBD_5_PT_1 : 16|6@1+ (1,0) [0|0] "" Vector__XXX
 SG_ DIAG_ST_OBD_5_PT_2 : 22|6@1+ (1,0) [0|0] "" Vector__XXX
 SG_ DIAG_ST_OBD_5_PT_3 : 28|6@1+ (1,0) [0|0] "" Vector__XXX
 SG_ DIAG_ST_OBD_5_PT_4 : 34|6@1+ (1,0) [0|0] "" Vector__XXX
 SG_ DIAG_ST_OBD_5_PT_5 : 40|6@1+ (1,0) [0|0] "" Vector__XXX
 SG_ DIAG_ST_OBD_5_PT_6 : 46|6@1+ (1,0) [0|0] "" Vector__XXX
 SG_ DIAG_ST_OBD_5_PT_7 : 52|6@1+ (1,0) [0|0] "" Vector__XXX
 SG_ DIAG_ST_OBD_5_PT_8 : 58|6@1+ (1,0) [0|0] "" Vector__XXX

BO_ 779 EDMEMsg30B: 8 EDME
 SG_ CRC_30B : 0|8@1+ (1,0) [0|255] "CRC" Vector__XXX
 SG_ ALIV_ST_ENG_STA_AUTO : 8|4@1+ (1,0) [0|14] "counter" Vector__XXX
 SG_ SPEC_TYP_ENGSTA : 32|4@1+ (1,0) [0|15] "" Vector__XXX

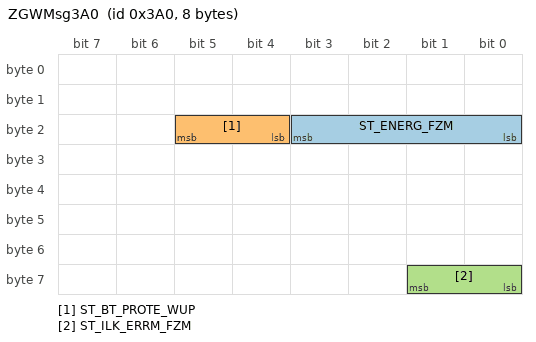
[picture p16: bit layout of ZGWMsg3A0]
BO_ 928 ZGWMsg3A0: 8 Vector__XXX
 SG_ ST_ENERG_FZM : 16|4@1+ (1,0) [0|15] "status" Vector__XXX
 SG_ ST_BT_PROTE_WUP : 20|2@1+ (1,0) [0|3] "status" Vector__XXX
 SG_ ST_ILK_ERRM_FZM : 56|2@1+ (1,0) [0|3] "status" Vector__XXX

BO_ 1426 EDMEMsg592: 8 EDME

BO_ 1062 SMEMsg426: 8 Vector__XXX
 SG_ ID_U_CELL_HVSTO M : 0|8@1+ (1,0) [0|0] "" Vector__XXX
 SG_ DT_U_CELL : 8|56@1+ (1,0) [0|0] "" Vector__XXX

CM_ BU_ SME "Battery Management Electronics";
CM_ BU_ EDME "Electrical Digital Motor Electronics";
CM_ BU_ REME "Range Extender Electrical Machine Electronics";
CM_ BU_ KLE "Convenience Charging Electronics";
CM_ BU_ GWS "Electronic Gear Selector Switch";
CM_ BU_ RDME "Range Extender Digital Engine Electronics";
CM_ BO_ 3221225472 "This is a message for not used signals, created by Vector CANdb++ DBC OLE DB Provider.";
CM_ SG_ 3221225472 Frame0_1D6 "0xF0 in logs";
CM_ SG_ 3221225472 Frame1_1D6 "0xC0 in logs";
CM_ SG_ 3221225472 frame0_1d6 "0xF0 in logs
";
CM_ SG_ 3221225472 frame1_1d6 "0xCC -> 0xC0 in logs";
CM_ SG_ 3221225472 Frame_0_1EE "0x00 in logs";
CM_ SG_ 3221225472 Frame_1_1EE "0xFC in logs";
CM_ SG_ 3221225472 POSITION_1 "Steering angle";
CM_ SG_ 3221225472 UnusedFF "Always 0xFF";
CM_ SG_ 3221225472 TemperatureMaxMaybe "Temperature might reside here";
CM_ BO_ 274 "10ms - Status Of High-Voltage Battery 2";
CM_ SG_ 274 DC_link "actual-value_voltage_Link";
CM_ SG_ 274 RQ_OPN_DCSW_HVSTO_ILY "request_open_disconnecting-switch_high-voltage-storage_instantl";
CM_ SG_ 274 Battery_Current "-819.2 ... 819 A
(PH) = 0.1 * (HEX) - 819.2 [A]";
CM_ SG_ 274 HVBatt_SOC "charging-condition_high-voltage-storage";
CM_ SG_ 274 LDST_HVSTO "Not used";
CM_ SG_ 274 RQ_OPC_CHG_HVSTO "request_open-circuit_charge_high-voltage-storage";
CM_ SG_ 274 RQ_OPN_DCSW_HVSTO_FAST "request_open_disconnecting-switch_high-voltage-storage_fas";
CM_ SG_ 274 CHGCOND_HVSTO_DELTA "charging-condition_high-voltage-storage_delta - The signal describes the delta between two SOC steps in the previous SOC signal";
CM_ BO_ 1001 "200ms - Main control for LIM
";
CM_ BO_ 1073 "200ms - Data High-Voltage Battery Unit";
CM_ SG_ 1073 ST_SER_DSCO_PLG "status_service_disconnection_plug";
CM_ SG_ 1073 ST_MEASMT_ISL "status_measurement_isolation";
CM_ SG_ 1073 RQ_ABRT_CHGNG "request_abort_charging";
CM_ SG_ 1073 PRD_DUR_CHGNG "prediction_duration_charging FFFF = signal unavailable";
CM_ SG_ 1073 PRD_T_EOCHG "prediction_time_end-of-charging";
CM_ SG_ 1073 ENC_HVSTO_MAX "energy-content_high-voltage-storage_maximum";
CM_ SG_ 1073 ST_CHGRDI_HVSTO "not used on i3";
CM_ BO_ 1074 "200ms - Battery SOC info";
CM_ SG_ 1074 REQ_OPMO_HYM_HVSTO "request_operating-mode_hybrid-master_high-voltage-storage";
CM_ SG_ 1074 TARGET_VOLTAGE_VC_MODE "target_voltage_voltage-controlled_mode - Target voltage specification to be adjusted in voltage-controlled mode";
CM_ SG_ 1074 REQ_CHGCOND_HVSTO_MIN "request_charging-condition_high-voltage-storage_minimum";
CM_ SG_ 1074 REQ_CHGCOND_HVSTO_MAX "request_charging-condition_high-voltage-storage_maximum";
CM_ SG_ 1074 DISPLAY_ACTUALVAL_CHGCOND_HVSTO "display_actual-value_charging-condition_high-voltage-storage";
CM_ BO_ 808 "1000ms - Counter (Relayed from KOMBI)";
CM_ BO_ 303 "100ms - Wake up message (Relayed from BDC)";
CM_ SG_ 303 ST_VEH_CON "status_vehicle_condition";
CM_ SG_ 303 ST_KL "status_klemme";
CM_ SG_ 303 ST_KL_DIV "status_klemme_diversified";
CM_ SG_ 303 ST_KL_30B "status_klemme_30b";
CM_ SG_ 303 ST_KL_15N "status_klemme_15n";
CM_ BO_ 1000 "1000ms - Diagnosis OBD engine control electrical";
CM_ SG_ 1000 RQ_MIL_DIAG_OBD_ENGMG_EL "request_MIL_diagnosis_OBD_engine-management-system_electric";
CM_ SG_ 1000 RQ_RST_OBD_DIAG "request_reset_OBD_diagnosis";
CM_ BO_ 816 "200ms - Range info";
CM_ BO_ 1072 "1s (Non periodic) - Charging status of high-voltage battery 2";
CM_ SG_ 1072 PRD_U_SRT_CHG_HVSTO "prediction_voltage_short-term_charge_high-voltage-storage";
CM_ SG_ 1072 PRD_U_SRT_DCHG_HVSTO "prediction_voltage_short-term_discharge_high-voltage-storage";
CM_ SG_ 1072 PRD_U_LT_CHG_HVSTO "prediction_voltage_long-term_charge_high-voltage-storage";
CM_ SG_ 1072 PRD_U_LT_DCHG_HVSTO "prediction_voltage_long-term_discharge_high-voltage-storage";
CM_ BO_ 506 "1s - Status Of High-Voltage Battery 1";
CM_ SG_ 506 ST_ERR_ISL_EXTN_BN_HV "status_error_isolation_external_Bordnetz_high-voltage";
CM_ SG_ 506 ST_ERR_ISL_INTL_BN_HV "status_error_isolation_internal_Bordnetz_high-voltage";
CM_ SG_ 506 RQ_COOL_HVSTO "request_cooling_high-voltage-storage";
CM_ SG_ 506 ST_VA_COOL_HVSTO "status_valve_cooling_high-voltage-storage";
CM_ SG_ 506 ST_ERR_LOKG_HVSTO "status_error_locking_high-voltage-storage";
CM_ SG_ 506 ST_PRCHRG_LOKD_HVSTO "status_precharge_locked_high-voltage-storage";
CM_ SG_ 506 ST_DCSW_HVSTO "status_disconnecting-switch_high-voltage-storage";
CM_ SG_ 506 ST_EMMOD_HVSTO "status_emergency-mode_high-voltage-storage";
CM_ SG_ 506 RQ_SER_HVSTO "request_service_high-voltage-storage";
CM_ SG_ 506 ERR_EMMOD_HVSTO "error_emergency-mode_high-voltage-storage";
CM_ SG_ 506 ST_ERR_DCSW_HVSTO "status_error_disconnecting-switch_high-voltage-storage";
CM_ SG_ 506 ST_WARN_ISL_BN_HV "status_warning_isolation_Bordnetz_high-voltage";
CM_ SG_ 506 ST_CSOV_HVSTO "status_cold-shut-off-valve_high-voltage-storage";
CM_ SG_ 506 AVL_TEMP_HVSTO "actual-value_temperature_high-voltage-storage";
CM_ SG_ 506 AVL_TEMP_HTEX_HVSTO "actual-value_temperature_heat-exchanger_high-voltage-storage";
CM_ SG_ 506 AVL_TEMP_HVSTO_MIN "actual-value_temperature_high-voltage-storage_minimum";
CM_ SG_ 506 AVL_TEMP_HVSTO_MAX "actual-value_temperature_high-voltage-storage_maximum";
CM_ BO_ 1037 "1s - Charging status of high-voltage storage 1";
CM_ SG_ 1037 AVLB_PWR_SRT_CHG_HVSTO "available_power_short-term_charge_high-voltage-storage Available electrical charging power of the high-voltage storage device, which is constant over a period of one second
can be recorded taking into account the charging current and charging voltage limits";
CM_ SG_ 1037 AVLB_PWR_SRT_DCHG_HVSTO "available_power_short-term_discharge_high-voltage-storage Available electrical discharge power of the high-voltage battery, which is constant over a period of one
Second can be delivered taking into account the discharge current and discharge voltage limits";
CM_ SG_ 1037 AVLB_PWR_LT_CHG_HVSTO "available_power_long-term_charge_high-voltage-storag Available electrical charging power of the high-voltage storage unit, which is constant over a period of five
Seconds can be recorded taking into account the charging current and charging voltage limits";
CM_ SG_ 1037 AVLB_PWR_LT_DCHG_HVSTO "available_power_long-term_discharge_high-voltage-storage Available electrical discharge power of the high-voltage battery, which is constant over a period of five
Seconds can be delivered taking into account the discharge current and discharge voltage limits
";
CM_ BO_ 767 "100ms - Status Heating High-Voltage Battery";
CM_ SG_ 767 AVL_PWR_HT_HVSTO "actual-value_power_heating_high-voltage-storage";
CM_ BO_ 569 "200ms - Data high voltage battery Unit 2";
CM_ SG_ 569 SYNCN_DT_HVSTO_2 "synchronization_data_high-voltage-storage_2 DTS Mapping:None;
Synchronization as feedback from HV storage (enumerating).
This signal is not sent by plug-in hybrids in SP2009";
CM_ SG_ 569 MUX_DT_HVSTO_2 "multiplexer_data_high-voltage-storage_2 DTS Mapping:None;
This signal is not sent by plug-in hybrids in SP2009.";
CM_ SG_ 569 PRD_ENERG_CHCOND_2_COS "prediction_Energy_charging-condition_2_consumer";
CM_ SG_ 569 PRD_ENERG_CHGTAR_2_HVSTO "prediction_Energy_charging-target_2_high-voltage-storage";
CM_ BO_ 701 "100ms - Status diagnosis high voltage 1";
CM_ SG_ 701 ALIV_ST_DIAG_HV_1 "alive_status_diagnosis_high-voltage_1 - counter 0...14";
CM_ SG_ 701 CHL_ST_DIAG_HV_1 "CHL_status_diagnosis_high-voltage_1 - counter 0...14";
CM_ SG_ 701 ST_DIAG_HV_ECU_1 "status_diagnosis_high-voltage_ECU_1";
CM_ BO_ 757 "100ms - High-Voltage Battery Charge/Discharge Limitations";
CM_ SG_ 757 U_MAX_CHG_HVSTO "voltage_maximum_charge_high-voltage-storage
60AH = 3936 , 94AH = 3964
";
CM_ SG_ 757 U_MIN_DCHG_HVSTO "voltage_minimum_discharge_high-voltage-storage
60AH = 2594 , 94AH = 2607";
CM_ SG_ 757 I_DYN_MAX_CHG_HVSTO "current_dynamic_maximum_charge_high-voltage-storage
99% 60AH 8280 , 48% 94AH 12072";
CM_ SG_ 757 I_DYN_MAX_DCHG_HVSTO "current_dynamic_maximum_discharge_high-voltage-storage 
99% 60AH 4102 , 48% 94AH 4429";
CM_ BO_ 962 "1s - Status diagnostics OBD 2 powertrain 94AH (not on 60AH)";
CM_ SG_ 962 ALIV_ST_DIAG_OBD_2_PT "alive_status_diagnosis_OBD_2_power-train";
CM_ SG_ 962 ST_DIAG_OBD_2_PT_MAX_MUX "status_diagnosis_OBD_2_power-train_maximum_multiplexer All diagnostic statuses of an ECU are summarized in one message. If more than 8 diagnosis
statuses are present, this content is multiplexed in the message.
This signal corresponds to the maximum value in the signal ST_DIAG_OBD_2_PT_IMME_MUX (between 4 and
60 possible values).";
CM_ SG_ 962 ST_DIAG_OBD_2_PT_IMME_MUX "status_diagnosis_OBD_2_power-train_immediate_multiplexer";
CM_ SG_ 962 DIAG_ST_OBD_2_PT_1 "diagnosis_status_OBD_2_power-train_1 Diagnostic status to transmit the status of the OBD error, Cal-ID, or CVN.
The content of the signal is transmitted via the signal Status_Diagnose_OBD_2_Antriebsstrang _Multiplexer_Aktuell
defined (multiplexing)";
CM_ SG_ 962 DIAG_ST_OBD_2_PT_2 "diagnosis_status_OBD_2_power-train_2 Diagnostic status to transmit the status of the OBD error, Cal-ID, or CVN.
The content of the signal is transmitted via the signal Status_Diagnose_OBD_2_Antriebsstrang _Multiplexer_Aktuell
defined (multiplexing)";
CM_ SG_ 962 DIAG_ST_OBD_2_PT_3 "diagnosis_status_OBD_2_power-train_3 Diagnostic status to transmit the status of the OBD error, Cal-ID, or CVN.
The content of the signal is transmitted via the signal Status_Diagnose_OBD_2_Antriebsstrang _Multiplexer_Aktuell
defined (multiplexing)";
CM_ SG_ 962 DIAG_ST_OBD_2_PT_4 "diagnosis_status_OBD_2_power-train_4 Diagnostic status to transmit the status of the OBD error, Cal-ID, or CVN.
The content of the signal is transmitted via the signal Status_Diagnose_OBD_2_Antriebsstrang _Multiplexer_Aktuell
defined (multiplexing)";
CM_ SG_ 962 DIAG_ST_OBD_2_PT_5 "diagnosis_status_OBD_2_power-train_5 Diagnostic status to transmit the status of the OBD error, Cal-ID, or CVN.
The content of the signal is transmitted via the signal Status_Diagnose_OBD_2_Antriebsstrang _Multiplexer_Aktuell
defined (multiplexing)";
CM_ SG_ 962 DIAG_ST_OBD_2_PT_6 "diagnosis_status_OBD_2_power-train_6 Diagnostic status to transmit the status of the OBD error, Cal-ID, or CVN.
The content of the signal is transmitted via the signal Status_Diagnose_OBD_2_Antriebsstrang _Multiplexer_Aktuell
defined (multiplexing)";
CM_ SG_ 962 DIAG_ST_OBD_2_PT_7 "diagnosis_status_OBD_2_power-train_7 Diagnostic status to transmit the status of the OBD error, Cal-ID, or CVN.
The content of the signal is transmitted via the signal Status_Diagnose_OBD_2_Antriebsstrang _Multiplexer_Aktuell
defined (multiplexing)";
CM_ SG_ 962 DIAG_ST_OBD_2_PT_8 "diagnosis_status_OBD_2_power-train_8 Diagnostic status to transmit the status of the OBD error, Cal-ID, or CVN.
The content of the signal is transmitted via the signal Status_Diagnose_OBD_2_Antriebsstrang _Multiplexer_Aktuell
defined (multiplexing)";
CM_ BO_ 1003 "1s - Status of charging high-voltage storage 3";
CM_ SG_ 1003 BEV_AVLB_PWR_SRT_CHG_HVSTO "BEV_available_power_short-term_charge_high-voltage-storag";
CM_ SG_ 1003 BEV_AVLB_PWR_SRT_DCHG_HVST0 "BEV_available_power_short-term_discharge_high-voltage-storage";
CM_ SG_ 1003 BEV_AVLB_PWR_LT_CHG_HVSTO "BEV_available_power_long-term_charge_high-voltage-storage";
CM_ SG_ 1003 BEV_AVLB_PWR_LT_DCHG_HVSTO "BEV_available_power_long-term_discharge_high-voltage-storage";
CM_ BO_ 867 "1s - Identification High-Voltage Battery";
CM_ SG_ 867 IDENT_HVSTO "dentification_high-voltage-storage";
CM_ BO_ 1287 "Stops after 5 messages sent (640ms) - Network management-2

This message is sent on the bus for sleep coordination purposes. If sent, falling asleep will occur
of the bus is delayed by the next 2 seconds";
CM_ SG_ 1287 NM2_AUTOSAR_RES_ACAN "NM2_AUTOSAR_reserved_A-CAN AUTOSAR - Warning. To be assigned a value of 00000000h.";
CM_ SG_ 1287 NM2_USR_DT_ACAN "NM2_user_data_A-CAN Contains additional user information that is important for diagnostic purposes.
Byte 7 must contain the diagnostic address of the control unit.
Byte 6 must contain 0x00 (reserved).
Byte 5 must contain the \"Most Significant Byte\" of the address of the function that keeps the bus awake.
Byte 4 must contain the \"Least Significant Byte\" of the address of the function that keeps the bus awake.
";
CM_ BO_ 1415 "5s - Services

The service message can be sent by several control devices and is a multiplex message.
To ensure that different identifiers are used, a \"base ID\" of 580h is used
(10110000000b) on the K-CAN and on the PT-CAN - the control unit address of the respective transmitter is added.
A 7-digit control unit address is used uniformly on the K-CAN and the PT-CAN.
The value transmitted in ID2 indicates which service is being transmitted. like bytes 1-7 too
are to be interpreted.
The triggering conditions (including debounce times) always refer to the ID2, not to the bus ID";
CM_ BO_ 1052 "1s - Status Of Operating Mode Of Hybrid 2";
CM_ SG_ 1052 T_OPN_DCSW_HVSTO "Not used on i3";
CM_ SG_ 1052 ST_COOL_HVSTO "status_cooling_high-voltage-storage";
CM_ SG_ 1052 AVL_U_SRTC_HVSTO "Not used on i3";
CM_ BO_ 1543 "100ms (Non periodic)";
CM_ BO_ 1017 "1s - Data drive train 2 (Also on K-CAN)";
CM_ SG_ 1017 ALIV_DT_PT_2 "alive_data_power-train_2 (counter 0...E) F=signal invalid";
CM_ SG_ 1017 ST_MOD_DRV "status_mode_drive";
CM_ SG_ 1017 ST_DRV_VEH "status_drive_vehicle - A possible definition of driving readiness in hybrid vehicles is via bit 7, bit 0 and bit 1 (If Bit 7 = 0, this means that an electric motor is installed and the vehicle is always ready to drive). A possible definition of driving readiness arises from vehicles with exclusively combustion engines via bit 0 and bit 1 (bit 7 is always at 1)";
CM_ SG_ 1017 ST_ENG_RUN_DRV "status_engine_run_drive";
CM_ SG_ 1017 ST_SW_CLT_DRV "status_switch_clutch_drive";
CM_ SG_ 1017 ST_ILK_STRT_DRV "status_interlock_starter_drive";
CM_ SG_ 1017 TEMP_ENG_DRV "temperature_engine_drive";
CM_ SG_ 1017 TEMP_EOI_DRV "temperature_engine-oil_drive";
CM_ SG_ 1017 ST_GRSEL_DRV "For manual transmissions, 1111b is usually sent in this signal and from use of the
For modular motors, this signal is provided with valid values ??0010b (= reverse gear) or 0000b (= no
reverse gear), or sent with 1111b if an error is diagnosed.";
CM_ BO_ 417 "20ms - Vehicle speed";
CM_ SG_ 417 ALIV_V_VEH "alive_speed_vehicle - Counter 0...14";
CM_ SG_ 417 ST_V_VEH_NSS "Not used on i3";
CM_ SG_ 417 V_VEH_COG "speed_vehicle_centre-of-gravity";
CM_ SG_ 417 QU_V_VEH_COG "Qualifier_speed_vehicle_centre-of-gravity

1000 Initialization Occurs during the initialization phase until actual value is available
(Pre-filling). Useful signal is permanently filled with use value 0.
0001
Signal value is valid and
secured and
plausibility checked
1001 Reserved
0010 Reserved
1010 signal value is valid,
Condition/status temporary
FUSI: A quantity necessary for calculating the speed is missing
(e.g. longitudinal acceleration, wheel speed,...). Signal quality at unstable
Travel restricted. (Applicability of the for safety-relevant functions
Check signal.)
0011 Reserved
1011
Signal quality or
surveillance
restricted,
Condition/status temporary
FUSI: More than one necessary for calculating speed
Size is missing (e.g. longitudinal acceleration, wheel speed,...). signal quality
limited by unstable driving. (For safety-related functions
Check applicability of signal.)
0100 Reserved
1100 Reserved
0110 Reserved
1110 Signal value is invalid,
Condition/status temporary
No wheel";
CM_ SG_ 417 DVCO_VEH "Not used on i3";
CM_ BO_ 896 "Stops after 3 messages on startup - VIN";
CM_ BO_ 704 "100ms - Status information combustion engine";
CM_ SG_ 704 TORQ_MAX_CENG "torque_maximum_combustion-engine";
CM_ SG_ 704 TORQ_MIN_CENG "torque_minimum_combustion-engine";
CM_ SG_ 704 RPM_MAX_CENG "RPM_maximum_combustion-engine";
CM_ SG_ 704 ST_INFO_CENG_REX "status_information_combustion-engine_range-extender

0--- ---1 Diagnostic routine is still running or not yet running
(Class 1)
0--- --1- Diagnostic routine is still running or not yet running
(2nd grade)
0--- -1-- Adaptation is still running or not yet running
0--- 1--- High AKF loading
0--1 ---- Cat heater required/active
0-1- ---- Exhaust gas temperature too high
1111
1110 Function interface_is_not_available Send function in operation, values ??not
available
1111
1101 Function_reports_error Sending function in operation, reports error
1111
1111 Signal_unfilled Transmission function not in operation";
CM_ SG_ 704 AVL_TEMP_CENG_REX "actual-value_temperature_combustion-engine_range-extender";
CM_ SG_ 704 DELTA_SOC_DYN "Not used on i3";
CM_ BO_ 165 "10ms";
CM_ BO_ 168 "10ms";
CM_ BO_ 205 "10ms";
CM_ BO_ 667 "100ms - Information about electric motor 1";
CM_ SG_ 667 ST_ERR_MOT_1 "status_error_motor_1

0000 0000 0000 0000 Normal operation
0--- ---- ---- ---1 Error-related AKS
141
0--- ---- ---- --1- Error-related freewheeling
0--- ---- ---- -1-- Error-related 0 torque control
0--- ---- ---- 1--- Limp Home
0--- ---- ---1 ---- Violation of memory limits (U_DC, I_DC)
0--- ---- --1- ---- Torque deviation EM
0--- ---- -1-- ---- Temperature error EM
0--- ---- 1--- ---- Interlock / crash clamp / emergency stop
0--- ---1 ---- ---- AC power error
0--- --1- ---- ---- Resolver error
0--- -1-- ---- ---- CAN signal failure
0--- 1--- ---- ---- Signal failure internal measured variables
0--1 ---- ---- ---- EWS error
0-1- ---- ---- ---- HW-related error LE
01-- ---- ---- ---- Temperature error LE
1111 1111 1111 1101 Signal not available
1111 1111 1111 1110 Error
1111 1111 1111 1111 Signal invalid";
CM_ SG_ 667 ST_INFO_MOT_1 "status_information_motor_1
0000 0000 0000 Normal operation
0--- ---- ---1 derating torque due to HV-DC voltage limit (motor mode)
0--- ---- --1- derating torque due to HV-DC voltage limit (generator mode)
0--- ---- -1-- derating torque due to speed (motor mode)
0--- ---- 1--- derating torque due to speed (generator mode)
0--- ---1 ---- derating torque due to HV-DC current limit (motor mode)
0--- --1- ---- derating torque due to HV-DC current limit (generator mode)
0--- -1-- ---- derating torque due to temperature electric machine
0--- 1--- ---- Info: derating torque due to inverter limit (motor/generator mode)
0--1 ---- ---- Info: Resolver offset not adjusted
0-1- ---- ---- Info: critical temperature end windings
01-- ---- ---- Info: critical temperature rotor
1111 1111 1101 Signal not available
1111 1111 1110 Error
1111 1111 1111 Signal invalid";
CM_ SG_ 667 RPM_MAX_MOT_1 "RPM_maximum_motor_1";
CM_ SG_ 667 ST_MSA_MOT_1 "status_MSA_motor_1";
CM_ SG_ 667 ST_INFO_DER_INVE_1 "status_information_derating_inverter_1

0000 0000 0000 0000 Normal operation
0--- ---- ---- ---1 Derating due to overtemperature IGBT/diode
0--- ---- ---- --1- Derating due to temperature spread NTC to IGBT/diode
0--- ---- ---- -1-- Derating due to overtemperature NTC
0--- ---- ---- 1--- Derating due to coolant overtemperature
0--- ---- ---1 ---- Derating due to switching overvoltage due to U_DC level
0--- ---- --1- ---- Derating due to speed range
0--- ---- -1-- ---- Derating due to current criterion/current-time area
143
0--- ---- 1--- ---- Derating due to temperature gradient violation
0--- ---1 ---- ---- Info: Short circuit UVW highside
0--- --1- ---- ---- Info: Short circuit UVW lowside
0--- -1-- ---- ---- Info: UVW switch open
0--- 1--- ---- ---- Info: Controller active
0--1 ---- ---- ---- Info: Id controller in anti-windup
0-1- ---- ---- ---- Info: Iq controller in anti-windup
1111 1111 1111 1101 Signal not available
1111 1111 1111 1110 Error
1111 1111 1111 1111 Signal invalid";
CM_ BO_ 668 "100ms";
CM_ BO_ 669 "100ms";
CM_ BO_ 407 "30ms - Status gear selector switch (Relayed from GWS on i8)";
CM_ SG_ 407 counter_197 "0-E increments each message";
CM_ BO_ 1290 "640ms - Network management-2 A-CAN";
CM_ SG_ 1290 NM2_AUTOSAR_RES_ACAN_50A "NM2_AUTOSAR_reserved_A-CAN";
CM_ SG_ 1290 NM2_USR_DT_ACAN_50A "NM2_user_data_A-CAN";
CM_ BO_ 748 "2s";
CM_ BO_ 1289 "Stops after 5 messages sent (640ms)";
CM_ BO_ 1075 "1s - High-voltage storage specification (Relayed from EME on i8)";
CM_ SG_ 1075 CTR_MEASMT_ISL "control_measurement_isolation";
CM_ SG_ 1075 ST_HT_HVSTO "status_heating_high-voltage-storage

00 Not defined
01 Battery heating not active
10 Battery heating active
11 Signal invalid";
CM_ SG_ 1075 RQ_EMMOD_HYB_HVSTO "request_emergency-mode_hybrid_high-voltage-storage

0000 no response (normal operation) no error or replacement response request
0--1 Reduction SOC-Min Reduction of the SOC minimum limit
0-1- Disable diagnoses due to
battery-free operation
01-- Emergency running reaction 3 Emergency charging active, 12V on-board network is connected via emergency charging power supply
Power electronics protected
1111 Signal invalid";
CM_ BO_ 339 "20ms";
CM_ BO_ 173 "10ms ";
CM_ BO_ 187 "10ms ";
CM_ BO_ 256 "10ms";
CM_ BO_ 264 "100ms - Actual Charging Electronics Data (Relayed from EME)";
CM_ SG_ 264 AVL_U_CHGE_ALTC_WR_1 "actual-value_voltage_charging-electronic_alternating-current_wire_1";
CM_ SG_ 264 RPM_CTRL_MOT_TRCT "RPM_controller_motor_traction";
CM_ SG_ 264 AVL_I_CHGE "actual-value_current_charging-electronic";
CM_ SG_ 264 ST_AC_CHGNG_EPRG "status_aircon_charging_emergency-program";
CM_ SG_ 264 RQ_I_DYNMC_LIM "request_current_dynamics_limit";
CM_ SG_ 264 AVL_OPMO_CHGE "actual-value_operating-mode_charging-electronic";
CM_ BO_ 317 "10ms ";
CM_ BO_ 267 "20ms - High-voltage storage circuit breaker";
CM_ SG_ 267 CRC_10B "CRC8_SAE_J1850_ZER0 formula, 0x1D Poly, initial value 0x3F, Final XOR value 0x0";
CM_ SG_ 267 ALIV_SPEC_DCSW_HVSTO "alive_specification_disconnecting-switch_high-voltage-storag - counter 0..E , F used to signal error";
CM_ SG_ 267 RQ_DCSW_HVSTO_CLO "request_disconnecting-switch_high-voltage-storage_close";
CM_ SG_ 267 ST_DCHG_LINK_2 "status_discharge_Link_2 - This signal is not sent when the ST_DCHG_LINK signal is sent.";
CM_ BO_ 318 "1s";
CM_ BO_ 402 "1s";
CM_ BO_ 695 "100ms";
CM_ BO_ 738 "1s (changes rate often)";
CM_ BO_ 744 "100ms";
CM_ BO_ 815 "200ms";
CM_ BO_ 932 "1s (Non periodic)";
CM_ BO_ 997 "10s Control of electric water heaters";
CM_ SG_ 997 ST_HV_RDI "status_high-voltage_readiness

0 High-voltage system not ready
1 high-voltage system ready and active
3 Signal invalid";
CM_ BO_ 1004 "1s - Possibility of engine start and engine stop";
CM_ SG_ 1004 ALIV_ST_PSBTY_ENGSTA_ENGSTP "alive_status_possibility_engine-start_engine-stop";
CM_ SG_ 1004 ENERG_BN_RDI_DRVG "Energy_Bordnetz_readiness_driving

0 No HV release
1 HV release (and no charging plug is inserted)
2 HV release and charging plug is inserted
3 HV release and charging plug unknown
4 No HV release and charging plug plugged in
5 No HV release and charging plug unknown
15 Signal invalid";
CM_ SG_ 1004 ST_PSBTY_ENGSTA_ENGSTP "status_possibility_engine-start_engine-stop";
CM_ SG_ 1004 V_VEH_MAX "speed_vehicle_maximum";
CM_ SG_ 1004 TAR_OPMO_GRB_2 "target_operating-mode_gearbox_2

0--1 No load requirement
0-1- Speed ??control request
1101 Signal not available
1110 error
1111 Signal invalid";
CM_ SG_ 1004 SPEC_DYNMC_GRB_2 "specification_dynamics_gearbox_2

0 Smooth (default)
1 Normal
2 Agressive
3 Signal invalid";
CM_ BO_ 1021 "100ms - Transmission data display";
CM_ SG_ 1021 ALIV_DT_DISP_GRDT "alive_data_display_gearbox-drive-train";
CM_ SG_ 1021 DISP_GR_GRB "display_gear_gearbox";
CM_ SG_ 1021 DISP_PRG_GRB "display_program_gearbox";
CM_ SG_ 1021 DISP_PO_IDC_GRB "display_position_indicate-direction_gearbox";
CM_ SG_ 1021 DISP_PO_GRB "display_position_gearbox";
CM_ SG_ 1021 DISP_SSC_IDC_GRB "display_shift-scheme_indicate-direction_gearbox";
CM_ SG_ 1021 GEN_IDLI "generator_indicator-light";
CM_ SG_ 1021 DISP_RQ_GR_GRB "display_request_gear_gearbox";
CM_ BO_ 1065 "50ms - Status DC/DC converter";
CM_ SG_ 1065 AVL_I_HV_DCDC "actual-value_current_high-voltage_DC/DC Instantaneous HV current of the DC/DC converter.
In Buck mode the current value is positive, in Boost mode it is negative.";
CM_ SG_ 1065 ST_CHGNG_HV_PWMG "status_charging_high-voltage_power-mangement
0000 0000 no request
0--- ---1 Lack of energy in the high-voltage storage
0--- --1- Aborted due to HV error
0--- -1-- Aborted due to DCDC failure
0--- 1--- Cyclic reloading ended by loading
0-10 ---- next cyclic charging possible
0-11 ---- next cyclic charging process no longer possible
1111 1111 Signal invalid";
CM_ BO_ 1298 "640ms";
CM_ BO_ 261 "10ms ";
CM_ SG_ 261 CRC8_105 "CRC8_SAE_J1850_ZER0 formula, 0x1D Poly, initial value 0x73 , Final XOR value 0x0";
CM_ BO_ 464 "1s - Drivetrain protection";
CM_ SG_ 464 RQ_REX_PWRD "request_range-extender_power-down

00 INIT
01 Do not allow torque build-up No REX operation permitted
10 Allow torque build-up REX operation permitted
11 Signal invalid";
CM_ SG_ 464 VRFD_RDI_DRVG "verified_readiness_driving

00 INIT
01 Torque build-up/cl. 50 not allowed
10 torque build-up/cl. 50 allow
11 Signal invalid";
CM_ SG_ 464 RQ_EAX_ABM_ENGMG "request_e-axis_absence-of-moments_engine-management-system

00 INIT
01 Do not allow moment build-up
10 Allow moment buildup
11 Signal invalid";
CM_ SG_ 464 DV_AVAI "driver_availibility

000 drivers present
001 Driver presence unknown
010 Driver absent
100 INIT
101 drivers present virtually
111 Signal invalid";
CM_ BO_ 414 "500ms (Relayed from EME)";
CM_ BO_ 1048 "1s - Status Hybrid 2";
CM_ SG_ 1048 ST_RSTA_DRV "status_race-start_drive

00 no race start active
01 Race start active
10 Not defined
11 Signal invalid";
CM_ SG_ 1048 CON_EWS_ENB "condition_EWS_enable

00 IMOB_LOCKED Ignition/injection locked
01 IMOB_UNLOCKED Ignition/injection released
10 IMOB_UNLOCKED_RETRY Ignition/injection released, authentication confirmation time
expired
11 Signal invalid";
CM_ SG_ 1048 RQ_EMMOD_HYB_DME_2 "request_emergency-mode_hybrid_DME_2

0000
0000 no reaction (normal operation) no error or
Substitute response request
0--- ---1 Transmission FID_EKK_RED
0--- --1- Transmission FID_EKK_DEAK
0--- -1-- Transmission FID_EGS_NMAX_LOW
0--- 1--- Transmission FID_EGS_NMAX_HIGH
00-1 ---
-
Transmission not ready to drive as requested
driver
001- ---
-
Cancel traction of gearbox 2 when exceeded
maximum electrical speed
0111 ---
- Do not cancel the traction of gearbox 2";
CM_ SG_ 1048 TAR_OPMO_MOT_TRCT "target_operating-mode_motor_traction

0 Standby can be interpreted as freewheeling or AKS on the part of the electric motor
become
1 torque control
3 EM voltage regulation
5 speed control with
Torque precontrol
6 HV battery current control
8 AKS Active short circuit
A Freewheel
D Reserved Value held for extended signal tag.
E Reserved Value held for extended signal tag.
F Signal invalid When converting the signal tag, this code is started with \"Signal
\"is unfilled\".";
CM_ SG_ 1048 TAR_DIRRT_MOT_TRCT "target_direction-of-rotation_motor_traction

0 no (target) direction of rotation
1 (target) direction of rotation forward
2 (setpoint) direction of rotation backwards Signal invalid/error
3 Signal invalid";
CM_ SG_ 1048 ST_OPR_RDI "status_operating_readiness

0--0 Electric machine 1 not ready for operation
0--1 E-machine 1 ready for operation
0-0- E-machine 2 not ready for operation
0-1- E-machine 2 ready for operation
1101 Reserved signal tag is not implemented.
Note: Reserved for functional identifier signal tag.
1110 Reserved signal tag is not implemented.
Note: Reserved for functional identifier signal tag.
1111 Signal_unfilled Transmission function not in operation";
CM_ BO_ 691 "100ms - Status start power drive";
CM_ BO_ 969 "1s (Non periodic)";
CM_ BO_ 1019 "1s - Data drive train 1";
CM_ SG_ 1019 AIP_ENG_DRV "not used on i3";
CM_ SG_ 1019 TAR_RPM_IDLG_DRV "not used on i3";
CM_ SG_ 1019 ST_SW_WAUP_D "not used on i3";
CM_ SG_ 1019 RDUC_DOCTR_RPM_D "not used on i3";
CM_ SG_ 1019 RQ_SHPA_GRB_REGE_P "not used on i3";
CM_ SG_ 1019 SLCTN_BUS_COMM_ENG_ "not used on i3";
CM_ SG_ 1019 RQ_STASS_ENGMG "not used on i3";
CM_ SG_ 1019 CTR_SLCK_DRV "not used on i3";
CM_ SG_ 1019 ST_RTIR_DRV "not used on i3";
CM_ SG_ 1019 ST_INFS_DRV "not used on i3";
CM_ SG_ 1019 RQ_SHPA_GRB_CHGB_LC "not used on i3";
CM_ SG_ 1019 ST_CAT_HT "status_CAT_heating";
CM_ SG_ 1019 ST_RDI_DRVG "status_readiness_driving";
CM_ SG_ 1019 TAR_RPM_IDLG_DRV_EXT "target_RPM_idling_drive_extended 0 ... 2540 1/min";
CM_ BO_ 1020 "5s - Data drive train 3";
CM_ SG_ 1020 ALIV_DT_PT_3 "Goes from 0..14";
CM_ SG_ 1020 TRNRAO_BAX "transmission-ratio_back-axle";
CM_ SG_ 1020 RLS_PLK_VRFD "release_park-lock_verified";
CM_ SG_ 1020 EXH_INSP_TST "exhaust_inspection_test";
CM_ BO_ 170 "10ms ";
CM_ BO_ 270 "20ms";
CM_ BO_ 336 "10ms";
CM_ BO_ 426 "50ms";
CM_ BO_ 529 "100ms";
CM_ BO_ 702 "100ms";
CM_ BO_ 714 "1s - On F10/F11 BMW this is (outside air temperature (Relayed from KOMBI))";
CM_ BO_ 739 "100ms";
CM_ BO_ 806 "500ms";
CM_ BO_ 935 "1s - Driving dynamics switch configuration";
CM_ SG_ 935 RQ_SU_SW_DRDY "request_setup_switch_driving-dynamics";
CM_ BO_ 970 "1s - Forecast trip information";
CM_ SG_ 970 FRC_AVR_HVSTO_PWR "forecast_average_high-voltage-storage_power";
CM_ SG_ 970 SYNCN_FRC_RD_INFO "synchronization_forecast_ride_information";
CM_ SG_ 970 MUX_FRC_RD_INFO "multiplexer_forecast_ride_information

3 comfort
4 sports
5 Sports+
7ECO Pro
8ECO Pro+
15 Signal invalid";
CM_ BO_ 976 "1s";
CM_ BO_ 1053 "1s - OBD request limitation torque";
CM_ SG_ 1053 INQY_LOWLIM_TORQ "inquiry_lower-limit_torque Lower torque limit of the desired loading torque. The signal is not used for OBD purposes";
CM_ SG_ 1053 INQY_UPLIM_TORQ "inquiry_upper-limit_torque Upper torque limit of the desired loading torque. The signal is not used for OBD purposes";
CM_ SG_ 1053 ACTVN_OBD_LIM_TORQ "Not used on i3";
CM_ BO_ 1301 "Stops after 5 messages sent (640ms)";
CM_ BO_ 1306 "640ms";
CM_ BO_ 1374 "Stops after 5 messages sent (640ms) - Networkmanagement-2 A-CAN";
CM_ BO_ 1434 "- Services";
CM_ BO_ 891 "10s - Enable cooling of high-voltage storage";
CM_ SG_ 891 RLS_COOL_HVSTO "release_cooling_high-voltage-storage";
CM_ SG_ 891 RQ_PAIC "request_park-air-conditioning";
CM_ SG_ 891 RQ_CSOV_HVSTO "request_cold-shut-off-valve_high-voltage-storage";
CM_ SG_ 891 ST_FRT_AC "status_front_aircon";
CM_ SG_ 891 AVL_I_EKK "actual-value_current_EKK";
CM_ BO_ 996 "10s - Electric water heater data";
CM_ SG_ 996 AVL_I_EL_GEY "actual-value_current_electric_geyser";
CM_ BO_ 1528 " - Services";
CM_ BO_ 411 "200ms - Control Crash";
CM_ SG_ 411 ST_EXCE_ACLN_THRV "status_exceeding_acceleration_threshold-value";
CM_ SG_ 411 CTR_PHTR_CR "control_park-heater_crash";
CM_ SG_ 411 CTR_PCSH_MST "control_precrash_maste";
CM_ SG_ 411 CTR_HAZW_CR "control_hazard-warning_crash";
CM_ SG_ 411 CTR_SWO_EKP_CR "control_switch-off_EKP_crash";
CM_ SG_ 411 CTR_CLSY_CR "control_central-locking-system_crash";
CM_ BO_ 965 " - Status diagnostics OBD 5 powertrain

Before SP2015: the first message is sent 500ms after terminal 15 is closed
take place.
From SP2015: the first message is sent 500ms after the message is ready to send
control unit and set active condition.
The 500ms is determined according to the internal time measurement.
Debounce time: tmin = 160.0 ms
Active condition = KL_15
Send condition = SIGNALCHANGE";
CM_ BO_ 779 "500ms - Status Motor Start Auto";
CM_ SG_ 779 ALIV_ST_ENG_STA_AUTO "alive_status_engine_start_AUTO counter 0...14";
CM_ SG_ 779 SPEC_TYP_ENGSTA "
specification_type_engine-start
0 No engine start requested
1 Start only by SGR SGR = starter generator
2 Start only by EM EM = E-machine
3 Start by SGR and EM SGR = starter generator
EM = electric machine
4 Start only by RS RS = pinion starter
5 Start only through ZaSta, ZuRS or similar change of mind capable
starter
ZaSta = timing belt starter
ZuRS= more startable
Pinion starter
15 Signal invalid";
CM_ BO_ 928 "5s - Vehicle condition";
CM_ SG_ 928 ST_ENERG_FZM "status_Energy_FZM
0 ENSTATE_GOOD
1 ENSTATE_OK
2 ENSTATE_SHORTAGE
3 ENSTATE_SEVERE_SHORTAGE
15 Signal invalid";
CM_ SG_ 928 ST_ILK_ERRM_FZM "status_interlock_error-memory_FZM

00 Error memory release Entry of errors without restrictions
01 Error memory lock The network error area must be locked
10 Reserve reserved for future expansion
11 Signal invalid";
CM_ BO_ 1426 "- Services";
CM_ BO_ 1062 "Polled message? Cellvoltages";
VAL_ 274 RQ_OPN_DCSW_HVSTO_ILY 0 "No statement possible" 1 "not active" 2 "active" 3 "Signal invalid" ;
VAL_ 274 RQ_OPC_CHG_HVSTO 0 "No statement possible. Diagnosis not yet completed" 1 "not active" 2 "active" 3 "Signal invalid" ;
VAL_ 274 RQ_OPN_DCSW_HVSTO_FAST 0 "No statement possible. Diagnosis not yet completed" 1 "not active" 2 "active" 3 "Signal invalid" ;
VAL_ 1001 Contactor_Con 0 "Open" 1 "OpenwithDiag" 2 "Close" 21 "Invalid" ;
VAL_ 1001 Chg_Status_Info 0 "No_charge" 1 "Init" 2 "Charge_active" 3 "Charge_pause" 4 "Charge_complete" 5 "Charge_error" 15 "Invalid" ;
VAL_ 1001 Chg_Readiness 0 "Not_Ready" 1 "Ready" 3 "Unavailable" ;
VAL_ 1001 Charge_Req 0 "No_Charge" 1 "PlugCharge" 2 "Timer" ;
VAL_ 1073 ST_SER_DSCO_PLG 1 "Service disconnect open" 2 "Service disconnect mounted" 3 "Signal invalid" ;
VAL_ 1073 ST_MEASMT_ISL 1 "Insulation measurement is not running" 2 "Insulation measurement is running" 3 "Signal invalid" ;
VAL_ 1073 RQ_ABRT_CHGNG 0 "No request" 1 "Request to interrupt charging" 2 "No charging possible, cooling requested" 3 "Signal invalid" ;
VAL_ 1074 REQ_OPMO_HYM_HVSTO 0 "No requirement" 1 "Adjust SoC" 2 "Voltage mode" 3 "Signal invalid" ;
VAL_ 303 CRC_12F 0 "No Description" ;
VAL_ 303 ST_VEH_CON 0 "Initial" 1 "Standby, driver absent" 2 "Basis operation, driver present" 3 "Basis operation, vehicle coasting" 4 "Engine postru" 5 "Ignition On" 6 "Ignition On, vehicle coasting" 7 "Engine On, vehicle not coasting" 8 "Driving " 9 "Impending start of engine" 10 "Impending start of engine, vehicle coasting" 11 "Start engine" 12 "Start engine, vehicle coasting" 13 "Car wash operation" 14 "Error" 15 "Signal invalid" ;
VAL_ 303 ST_KL 0 "Init" 1 "Reserve" 2 "KL30" 3 "KL30F-Change" 4 "KL30F-A" 5 "KL30B-Change" 6 "KL30B-A" 7 "KLR-Change" 8 "KLR-A" 9 "KL15-Change" 10 "KL15-A" 11 "KL50-Delay" 12 "KL50-Change" 13 "KL50-A" 14 "Mistake" 15 "Signal invalid" ;
VAL_ 303 ST_KL_DIV 0 "KL_DIV_INIT" 1 "KL_DIV_IDLE" 2 "KL_DIV_REQUEST" 3 "KL_DIV_RELEASED" 4 "KL_DIV_SAVED" 5 "KL_DIV_WAIT_NVM" 6 "KL_DIV_WAIT_VALID" 7 "KL_DIV_RELEASE_TRIG" 8 "KL_DIV_VALID_IDLE" 9 "KL_DIV_BLOCKED" 10 "KL_DIV_FAILURE_CP" 11 "KL_DIV_TIMEOUT_CP" 12 "KL_DIV_INVALID_CP" 13 "KL_DIV_TIMEOUT" 14 "KL_DIV_FAILURE" 15 "KL_DIV_INVALID" ;
VAL_ 303 ST_KL_30B 0 "init value" 1 "KL30BAus" 2 "Overrun greater than 0s and less than or equal to 1 s" 3 "Overrun greater than 1s and less than or equal to 5 s" 4 "Overrun greater than 5s and less than or equal to 10 s" 5 "Overrun greater than 10s and less than or equal to 20 s" 6 "Overrun greater than 20s and less than or equal to 30 s" 7 "Overrun greater than 30s and less than or equal to 40 s" 8 "Overrun greater than 40s and less than or equal to 50 s" 9 "Overrun greater than 50s and less than or equal to 1 min" 10 "Overrun greater than 1 minute and less than or equal to 5 minutes" 11 "Overrun greater than 5 minutes and less than or equal to 10 minutes" 12 "Overrun greater than 10min" 13 "KL30B permanent on" 14 "error" 15 "signal invalid" ;
VAL_ 1000 RQ_MIL_DIAG_OBD_ENGMG_EL 0 "No_Reset" 2 "Reset" ;
VAL_ 1000 RQ_RST_OBD_DIAG 0 "No request for reset OBD_diagnosis" 2 "Request Reset OBD_Diagnosis" 3 "Signal invalid" ;
VAL_ 506 ST_ERR_ISL_EXTN_BN_HV 0 "No statement possible. Diagnosis not yet completed" 1 "not active" 2 "active" 3 "Signal invalid" ;
VAL_ 506 ST_ERR_ISL_INTL_BN_HV 0 "No statement possible. Diagnosis not yet completed" 1 "not active" 2 "active" 3 "Signal invalid" ;
VAL_ 506 RQ_COOL_HVSTO 0 "no cooling requested Cell temperature is within normal operating range" 1 "Cooling requested SME requests release to open the refrigerant shut-off valve" 2 "Cooling urgent
 necessary SME urgently requests clearance to open the refrigerant shut-off valve
at" 3 "Signal invalid" ;
VAL_ 506 ST_VA_COOL_HVSTO 0 "No statement possible. Diagnosis not yet completed" 1 "not active Cooling valve closed" 2 "active cooling valve open" 3 "Signal invalid" ;
VAL_ 506 ST_ERR_LOKG_HVSTO 0 "No statement possible. Diagnosis not yet completed" 1 "not active No interlock error" 2 "active interlock error" 3 "Signal invalid" ;
VAL_ 506 ST_PRCHRG_LOKD_HVSTO 0 "No statement possible" 1 "not active Subpoena not blocked" 2 "active summons temporarily blocked" 3 "Signal invalid" ;
VAL_ 506 ST_DCSW_HVSTO 0 "Circuit breaker open OPN" 1 "Circuit breaker on pre-charge PRECHRG" 2 "circuit breaker closed CLS" 3 "Signal invalid SNA" ;
VAL_ 506 ST_EMMOD_HVSTO 0 "No statement possible. Diagnosis not yet completed" 1 "not active" 2 "active" 3 "Signal invalid" ;
VAL_ 506 RQ_SER_HVSTO 0 "No statement possible. Diagnosis not yet completed" 1 "not active" 2 "active" 3 "Signal invalid" ;
VAL_ 506 ERR_EMMOD_HVSTO 0 "No statement possible. Diagnosis not yet completed" 1 "not active" 2 "active" 3 "Signal invalid" ;
VAL_ 506 ST_ERR_DCSW_HVSTO 0 "no switching contact sticks" 1 "a switching contact sticks" 2 "stick two switching contacts" 3 "Signal invalid" ;
VAL_ 506 ST_WARN_ISL_BN_HV 0 "no statement possible" 1 "not active" 2 "active" 3 "Signal invalid" ;
VAL_ 506 ST_CSOV_HVSTO 0 "OK" 1 "Short circuit to ground" 2 "Short circuit to U_Bat" 3 "Line break" 6 "Driver error Only used in Gen2.0" 12 "Valve cannot be opened (stuck) Only operated in Gen2.0" 11 "Valve cannot be closed (stuck) Only operated in Gen2.0" 15 "Signal invalid" ;
VAL_ 569 MUX_DT_HVSTO_2 3 "Komfort" 4 "Sport" 5 "Sport +" 7 "ECO Pro" 8 "ECO Pro+" 15 "signal invalid" ;
VAL_ 701 ST_DIAG_HV_ECU_1 0 "HV diagnosis OK" 1 "HV protection function error" 2 "Diagnosis not yet expired" 13 "Reserved Note: Reserved for functional identifier signal tag" 14 "Reserved Note: Reserved for functional identifier signal tag" 15 "Signal_unfilled Transmission function not in operation" ;
VAL_ 1052 ST_COOL_HVSTO 0 "No statement possible" 1 "Cooling works" 2 "Cooling does not start despite request" 3 "Signal invalid" ;
VAL_ 1017 ST_MOD_DRV 0 "Standard" 1 "Sport" 2 "Eco" 3 "Komfort" 4 "EV" 13 "Reserved" 14 "Reserved" 16 "Signal Invalid" ;
VAL_ 667 ST_MSA_MOT_1 253 "signal not available" 254 "error" 255 "signal invalid" ;
VAL_ 264 ST_AC_CHGNG_EPRG 0 "disabled" 1 "activates emergency charging active, 12V on-board network is protected by emergency charging power supply in AE" 3 "Signal invalid" ;
VAL_ 264 RQ_I_DYNMC_LIM 0 "no dynamic limitation requested" 1 "Dynamic limitation requested" 3 "Signal invalid" ;
VAL_ 264 AVL_OPMO_CHGE 1 "standby" 2 "DC HV charging" 3 "Derating" 4 "charging interruption" 5 "errors" 6 "Crash" 7 "operating mode change" 8 "Load initialization" 9 "Load initialization completed" 13 "Function_interface_is_not_available Send function in operation, values ??not available" 14 "Function_reports_error Sending function in operation, reports error" 15 "Signal_unfilled Transmission function not in operation" ;
VAL_ 267 RQ_DCSW_HVSTO_CLO 0 "No request" 1 "Request ON" 3 "Signal invalid" ;
VAL_ 267 ST_DCHG_LINK_2 0 "Not active, no discharge" 1 "Active, discharge in progress" 3 "Signal Invalid" ;
VAL_ 1021 DISP_GR_GRB 0 "Darkswitching" 1 "1st gear" 2 "2nd gear" 3 "3rd gear" 4 "4th gear" 5 "5th gear" 6 "6th gear" 7 "7th gear" 8 "8th gear" 9 "9th gear" 15 "Invalid value" ;
VAL_ 1021 DISP_PRG_GRB 0 "darkswitching" 1 "Sport Mode" 2 "M-Program" 3 "L-program" 4 "City-program" 6 "Signal invalid" ;
VAL_ 1021 DISP_PO_IDC_GRB 0 "Not flashing" 1 "Flashing" 3 "Signal invalid" ;
VAL_ 1021 DISP_PO_GRB 0 "Darkswitch (off)" 1 "P" 2 "R" 3 "N" 4 "D" 6 "Signal Invalid" ;
VAL_ 1021 DISP_SSC_IDC_GRB 0 "Not flashing" 1 "Flashing" 3 "Signal invalid" ;
VAL_ 1021 GEN_IDLI 0 "Inactive" 1 "Active" 3 "Signal Invalid" ;
VAL_ 1021 DISP_RQ_GR_GRB 0 "Darkswitching" 1 "1st" 2 "2nd" 3 "3rd" 4 "4th" 5 "5th" 6 "6th" 7 "7th" 8 "8th" 9 "9th" 13 "Reserved" 14 "Reserved" 15 "Signal invalid" ;
VAL_ 1019 ST_CAT_HT 0 "Cat does not heat actively" 1 "Cat heater with traction active" 2 "Cat heaters with friction-free operation necessary/active" 3 "Invalid value" ;
VAL_ 1019 ST_RDI_DRVG 0 "Not ready to drive" 1 "Ready to drive" 3 "Value not valid" ;
VAL_ 1020 RLS_PLK_VRFD 0 "No statement" 1 "Release not granted" 2 "Release granted" 3 "Signal invalid" ;
VAL_ 1020 EXH_INSP_TST 0 "Test not active" 1 "Test active" 3 "Signal invalid" ;
VAL_ 1062 ID_U_CELL_HVSTO 0 "Voltages 1" 2 "Voltages 2" 3 "Voltages 3" 4 "Voltages 4" 5 "Voltages 5" 6 "Voltages 6" 7 "Voltages 7" 8 "Voltages 8" 9 "Voltages 9" 10 "Voltages 10" 11 "Voltages 11" 12 "Voltages 12" 13 "Voltages 13" 14 "Voltages 14" ;
